AUTOSAR XML (schema 4-3-0)
package /VehicleProject
  system System
    system mapping System_MPPNG
      data-mappings:
        sender-receiver-to-signal-mapping={data-element=SwitchDetectionNeeded2L3.SwitchDetectionNeeded2L3, system-signal=SwitchDetectionNeeded2L3}
        sender-receiver-to-signal-mapping={data-element=FSP1SwitchStatusL3.FSP1SwitchStatusL3, system-signal=FSP1SwitchStatusL3}
        sender-receiver-to-signal-mapping={data-element=FSP2SwitchStatusL3.FSP2SwitchStatusL3, system-signal=FSP2SwitchStatusL3}
        sender-receiver-to-signal-mapping={data-element=FSP2DiagInfoL3.FSP2DiagInfoL3, system-signal=FSP2DiagInfoL3}
        sender-receiver-to-signal-mapping={data-element=FSP1ResponseErrorL3.FSP1ResponseErrorL3, system-signal=FSP1ResponseErrorL3}
        sender-receiver-to-signal-mapping={data-element=LIN_TCP_KnobPostionStatus.LIN_TCP_KnobPostionStatus, system-signal=LIN_TCP_KnobPostionStatus}
        sender-receiver-to-signal-mapping={data-element=SwitchDetectionNeeded1L3.SwitchDetectionNeeded1L3, system-signal=SwitchDetectionNeeded1L3}
        sender-receiver-to-signal-mapping={data-element=FSP1DiagInfoL3.FSP1DiagInfoL3, system-signal=FSP1DiagInfoL3}
        sender-receiver-to-signal-mapping={data-element=SwitchDetectionResp2L3.SwitchDetectionResp2L3, system-signal=SwitchDetectionResp2L3}
        sender-receiver-to-signal-mapping={data-element=SwitchDetectionResp1L3.SwitchDetectionResp1L3, system-signal=SwitchDetectionResp1L3}
        sender-receiver-to-signal-mapping={data-element=ResponseErrorTCP.ResponseErrorTCP, system-signal=ResponseErrorTCP}
        sender-receiver-to-signal-mapping={data-element=LIN_TCP_ABS_ButtonStatus.LIN_TCP_ABS_ButtonStatus, system-signal=LIN_TCP_ABS_ButtonStatus}
        sender-receiver-to-signal-mapping={data-element=LIN_TCP_TCS_ButtonStatus.LIN_TCP_TCS_ButtonStatus, system-signal=LIN_TCP_TCS_ButtonStatus}
        sender-receiver-to-signal-mapping={data-element=FSP2ResponseErrorL3.FSP2ResponseErrorL3, system-signal=FSP2ResponseErrorL3}
        sender-receiver-to-signal-mapping={data-element=DiagInfoTCP.DiagInfoTCP, system-signal=DiagInfoTCP}
        sender-receiver-to-signal-mapping={data-element=LIN_TCP_ATC_ButtonStatus.LIN_TCP_ATC_ButtonStatus, system-signal=LIN_TCP_ATC_ButtonStatus}
        sender-receiver-to-signal-mapping={data-element=LIN_TCP_ESC_ButtonStatus.LIN_TCP_ESC_ButtonStatus, system-signal=LIN_TCP_ESC_ButtonStatus}
        sender-receiver-to-signal-mapping={data-element=ATC_Indication.ATC_Indication, system-signal=ATC_Indication}
        sender-receiver-to-signal-mapping={data-element=ABS_Indication.ABS_Indication, system-signal=ABS_Indication}
        sender-receiver-to-signal-mapping={data-element=ESC_Indication.ESC_Indication, system-signal=ESC_Indication}
        sender-receiver-to-signal-mapping={data-element=FSP1IndicationCmdL3.FSP1IndicationCmdL3, system-signal=FSP1IndicationCmdL3}
        sender-receiver-to-signal-mapping={data-element=TCS_Indication.TCS_Indication, system-signal=TCS_Indication}
        sender-receiver-to-signal-mapping={data-element=FSP2IndicationCmdL3.FSP2IndicationCmdL3, system-signal=FSP2IndicationCmdL3}
        sender-receiver-to-signal-mapping={data-element=Debug_PVT_SCIM_Ctrl_BHS3.Debug_PVT_SCIM_Ctrl_BHS3, system-signal=Debug_PVT_SCIM_Ctrl_BHS3}
        sender-receiver-to-signal-mapping={data-element=Debug_PVT_SCIM_Ctrl_BHS2.Debug_PVT_SCIM_Ctrl_BHS2, system-signal=Debug_PVT_SCIM_Ctrl_BHS2}
        sender-receiver-to-signal-mapping={data-element=Debug_PVT_SCIM_Ctrl_BHS1.Debug_PVT_SCIM_Ctrl_BHS1, system-signal=Debug_PVT_SCIM_Ctrl_BHS1}
        sender-receiver-to-signal-mapping={data-element=Debug_PVT_SCIM_Ctrl_BHS4.Debug_PVT_SCIM_Ctrl_BHS4, system-signal=Debug_PVT_SCIM_Ctrl_BHS4}
        sender-receiver-to-signal-mapping={data-element=Debug_PVT_SCIM_RD_BHS3_Volt.Debug_PVT_SCIM_RD_BHS3_Volt, system-signal=Debug_PVT_SCIM_RD_BHS3_Volt}
        sender-receiver-to-signal-mapping={data-element=Debug_PVT_SCIM_RD_BHS1_Volt.Debug_PVT_SCIM_RD_BHS1_Volt, system-signal=Debug_PVT_SCIM_RD_BHS1_Volt}
        sender-receiver-to-signal-mapping={data-element=Debug_PVT_SCIM_RD_BHS3_Fault.Debug_PVT_SCIM_RD_BHS3_Fault, system-signal=Debug_PVT_SCIM_RD_BHS3_Fault}
        sender-receiver-to-signal-mapping={data-element=Debug_PVT_SCIM_RD_BHS1_Fault.Debug_PVT_SCIM_RD_BHS1_Fault, system-signal=Debug_PVT_SCIM_RD_BHS1_Fault}
        sender-receiver-to-signal-mapping={data-element=Debug_PVT_SCIM_RD_BHS2_Fault.Debug_PVT_SCIM_RD_BHS2_Fault, system-signal=Debug_PVT_SCIM_RD_BHS2_Fault}
        sender-receiver-to-signal-mapping={data-element=Debug_PVT_SCIM_RD_BHS2_Volt.Debug_PVT_SCIM_RD_BHS2_Volt, system-signal=Debug_PVT_SCIM_RD_BHS2_Volt}
        sender-receiver-to-signal-mapping={data-element=Debug_PVT_SCIM_RD_BHS4_Fault.Debug_PVT_SCIM_RD_BHS4_Fault, system-signal=Debug_PVT_SCIM_RD_BHS4_Fault}
        sender-receiver-to-signal-mapping={data-element=Debug_PVT_SCIM_RD_BHS4_Volt.Debug_PVT_SCIM_RD_BHS4_Volt, system-signal=Debug_PVT_SCIM_RD_BHS4_Volt}
        sender-receiver-to-signal-mapping={data-element=Debug_PVT_SCIM_Ctrl_DaiPullUp.Debug_PVT_SCIM_Ctrl_DaiPullUp, system-signal=Debug_PVT_SCIM_Ctrl_DAIPullUp}
        sender-receiver-to-signal-mapping={data-element=Debug_PVT_SCIM_RD_ADI09.Debug_PVT_SCIM_RD_ADI09, system-signal=Debug_PVT_SCIM_RD_ADI09}
        sender-receiver-to-signal-mapping={data-element=Debug_PVT_SCIM_RD_ADI16.Debug_PVT_SCIM_RD_ADI16, system-signal=Debug_PVT_SCIM_RD_ADI16}
        sender-receiver-to-signal-mapping={data-element=Debug_PVT_SCIM_RD_ADI07.Debug_PVT_SCIM_RD_ADI07, system-signal=Debug_PVT_SCIM_RD_ADI07}
        sender-receiver-to-signal-mapping={data-element=Debug_PVT_SCIM_RD_ADI02.Debug_PVT_SCIM_RD_ADI02, system-signal=Debug_PVT_SCIM_RD_ADI02}
        sender-receiver-to-signal-mapping={data-element=Debug_PVT_SCIM_RD_DAI1.Debug_PVT_SCIM_RD_DAI1, system-signal=Debug_PVT_SCIM_RD_DAI1}
        sender-receiver-to-signal-mapping={data-element=Debug_PVT_SCIM_RD_ADI10.Debug_PVT_SCIM_RD_ADI10, system-signal=Debug_PVT_SCIM_RD_ADI10}
        sender-receiver-to-signal-mapping={data-element=Debug_PVT_SCIM_RD_ADI06.Debug_PVT_SCIM_RD_ADI06, system-signal=Debug_PVT_SCIM_RD_ADI06}
        sender-receiver-to-signal-mapping={data-element=Debug_PVT_SCIM_RD_ADI01.Debug_PVT_SCIM_RD_ADI01, system-signal=Debug_PVT_SCIM_RD_ADI01}
        sender-receiver-to-signal-mapping={data-element=Debug_PVT_SCIM_RD_ADI03.Debug_PVT_SCIM_RD_ADI03, system-signal=Debug_PVT_SCIM_RD_ADI03}
        sender-receiver-to-signal-mapping={data-element=Debug_PVT_SCIM_RD_ADI11.Debug_PVT_SCIM_RD_ADI11, system-signal=Debug_PVT_SCIM_RD_ADI11}
        sender-receiver-to-signal-mapping={data-element=Debug_PVT_SCIM_RD_ADI14.Debug_PVT_SCIM_RD_ADI14, system-signal=Debug_PVT_SCIM_RD_ADI14}
        sender-receiver-to-signal-mapping={data-element=Debug_PVT_SCIM_RD_ADI13.Debug_PVT_SCIM_RD_ADI13, system-signal=Debug_PVT_SCIM_RD_ADI13}
        sender-receiver-to-signal-mapping={data-element=Debug_PVT_SCIM_RD_ADI04.Debug_PVT_SCIM_RD_ADI04, system-signal=Debug_PVT_SCIM_RD_ADI04}
        sender-receiver-to-signal-mapping={data-element=Debug_PVT_SCIM_RD_ADI12.Debug_PVT_SCIM_RD_ADI12, system-signal=Debug_PVT_SCIM_RD_ADI12}
        sender-receiver-to-signal-mapping={data-element=Debug_PVT_SCIM_RD_ADI15.Debug_PVT_SCIM_RD_ADI15, system-signal=Debug_PVT_SCIM_RD_ADI15}
        sender-receiver-to-signal-mapping={data-element=Debug_PVT_SCIM_RD_ADI05.Debug_PVT_SCIM_RD_ADI05, system-signal=Debug_PVT_SCIM_RD_ADI05}
        sender-receiver-to-signal-mapping={data-element=Debug_PVT_SCIM_RD_DAI2.Debug_PVT_SCIM_RD_DAI2, system-signal=Debug_PVT_SCIM_RD_DAI2}
        sender-receiver-to-signal-mapping={data-element=Debug_PVT_SCIM_RD_ADI08.Debug_PVT_SCIM_RD_ADI08, system-signal=Debug_PVT_SCIM_RD_ADI08}
        sender-receiver-to-signal-mapping={data-element=LIN_BunkH2RoofhatchCloseBtn_St.LIN_BunkH2RoofhatchCloseBtn_St, system-signal=LIN_BunkH2RoofhatchCloseBtn_St}
        sender-receiver-to-signal-mapping={data-element=LIN_BunkH2LockButtonStatus.LIN_BunkH2LockButtonStatus, system-signal=LIN_BunkH2LockButtonStatus}
        sender-receiver-to-signal-group-mapping={data-element=LIN_AlmClkSetCurAlm_rqst_sg.LIN_AlmClkSetCurAlm_rqst_sg, signal-group=LIN_AlmClkSetCurAlm_rqst_sg, type-mapping=sender-rec-record-type-mapping=record-element-mappings=[{implementation-record-element=LIN_AlmClkSetCurAlm_rqst_SetMin, system-signal=LIN_AlmClkSetCurAlm_rqst_SetMin}, {implementation-record-element=LIN_AlmClkSetCurAlm_rqst_Type, system-signal=LIN_AlmClkSetCurAlm_rqst_Type}, {implementation-record-element=LIN_AlmClkSetCurAlm_rqst_ID, system-signal=LIN_AlmClkSetCurAlm_rqst_ID}, {implementation-record-element=LIN_AlmClkSetCurAlm_rqst_SetHr, system-signal=LIN_AlmClkSetCurAlm_rqst_SetHr}, {implementation-record-element=LIN_AlmClkSetCurAlm_rqst_Stat, system-signal=LIN_AlmClkSetCurAlm_rqst_Stat}]}
        sender-receiver-to-signal-mapping={data-element=LIN_BunkH2IntLightIncBtn_stat.LIN_BunkH2IntLightIncBtn_stat, system-signal=LIN_BunkH2IntLightIncBtn_stat}
        sender-receiver-to-signal-mapping={data-element=LIN_BunkH2Fade_ButtonStatus.LIN_BunkH2Fade_ButtonStatus, system-signal=LIN_BunkH2Fade_ButtonStatus}
        sender-receiver-to-signal-mapping={data-element=SwitchDetectionNeeded1L1.SwitchDetectionNeeded1L1, system-signal=SwitchDetectionNeeded1L1}
        sender-receiver-to-signal-mapping={data-element=LIN_BunkH2PowerWinOpenPSBtn_st.LIN_BunkH2PowerWinOpenPSBtn_st, system-signal=LIN_BunkH2PowerWinOpenPSBtn_st}
        sender-receiver-to-signal-mapping={data-element=LIN_IntLghtDimmingLvlDecBtn_s.LIN_IntLghtDimmingLvlDecBtn_s, system-signal=LIN_IntLghtDimmingLvlDecBtn_s}
        sender-receiver-to-signal-mapping={data-element=LIN_IntLghtDimmingLvlIncBtn_s.LIN_IntLghtDimmingLvlIncBtn_s, system-signal=LIN_IntLghtDimmingLvlIncBtn_s}
        sender-receiver-to-signal-mapping={data-element=ResponseErrorLECM2.ResponseErrorLECM2, system-signal=ResponseErrorLECM2}
        sender-receiver-to-signal-group-mapping={data-element=LIN_BunkH2PHTi_rqs_sg.LIN_BunkH2PHTi_rqs_sg, signal-group=LIN_BunkH2PHTi_rqs_sg, type-mapping=sender-rec-record-type-mapping=record-element-mappings=[{implementation-record-element=LIN_BunkH2PHTi_rqs_StartTimeHr, system-signal=LIN_BunkH2PHTi_rqs_StartTimeHr}, {implementation-record-element=LIN_BunkH2PHTi_rqs_Timer_cmd, system-signal=LIN_BunkH2PHTi_rqs_Timer_cmd}, {implementation-record-element=LIN_BunkH2PHTi_rqs_DurnTimeHr, system-signal=LIN_BunkH2PHTi_rqs_DurnTimeHr}, {implementation-record-element=LIN_BunkH2PHTi_rqs_StartTimeMin, system-signal=LIN_BunkH2PHTi_rqs_StartTimeMin}, {implementation-record-element=LIN_BunkH2PHTi_rqs_DurnTimeMin, system-signal=LIN_BunkH2PHTi_rqs_DurnTimeMin}]}
        sender-receiver-to-signal-mapping={data-element=ResponseErrorLECMBasic.ResponseErrorLECMBasic, system-signal=ResponseErrorLECMBasic}
        sender-receiver-to-signal-mapping={data-element=LIN_BunkH2VolumeDown_ButtonSta.LIN_BunkH2VolumeDown_ButtonSta, system-signal=LIN_BunkH2VolumeDown_ButtonSta}
        sender-receiver-to-signal-mapping={data-element=LIN_BunkH2IntLightDecBtn_stat.LIN_BunkH2IntLightDecBtn_stat, system-signal=LIN_BunkH2IntLightDecBtn_stat}
        sender-receiver-to-signal-mapping={data-element=FSP2DiagInfoL1.FSP2DiagInfoL1, system-signal=FSP2DiagInfoL1}
        sender-receiver-to-signal-mapping={data-element=LIN_BunkBAudioOnOff_ButtonStat.LIN_BunkBAudioOnOff_ButtonStat, system-signal=LIN_BunkBAudioOnOff_ButtonStat}
        sender-receiver-to-signal-mapping={data-element=DiagInfoLECM2.DiagInfoLECM2, system-signal=DiagInfoLECM2}
        sender-receiver-to-signal-mapping={data-element=SwitchDetectionNeeded2L1.SwitchDetectionNeeded2L1, system-signal=SwitchDetectionNeeded2L1}
        sender-receiver-to-signal-mapping={data-element=DiagInfoLECMBasic.DiagInfoLECMBasic, system-signal=DiagInfoLECMBasic}
        sender-receiver-to-signal-mapping={data-element=LIN_BunkBVolumeDown_ButtonStat.LIN_BunkBVolumeDown_ButtonStat, system-signal=LIN_BunkBVolumeDown_ButtonStat}
        sender-receiver-to-signal-mapping={data-element=LIN_IntLghtModeSelrFreeWheel_s.LIN_IntLghtModeSelrFreeWheel_s, system-signal=LIN_IntLghtModeSelrFreeWheel_s}
        sender-receiver-to-signal-mapping={data-element=LIN_BunkH2OnOFF_ButtonStatus.LIN_BunkH2OnOFF_ButtonStatus, system-signal=LIN_BunkH2OnOFF_ButtonStatus}
        sender-receiver-to-signal-mapping={data-element=FSP1ResponseErrorL1.FSP1ResponseErrorL1, system-signal=FSP1ResponseErrorL1}
        sender-receiver-to-signal-mapping={data-element=LIN_BunkH2VolumeUp_ButtonStatu.LIN_BunkH2VolumeUp_ButtonStatu, system-signal=LIN_BunkH2VolumeUp_ButtonStatu}
        sender-receiver-to-signal-mapping={data-element=ResponseErrorILCP1.ResponseErrorILCP1, system-signal=ResponseErrorILCP1}
        sender-receiver-to-signal-mapping={data-element=LIN_BunkH2Phone_ButtonStatus.LIN_BunkH2Phone_ButtonStatus, system-signal=LIN_BunkH2Phone_ButtonStatus}
        sender-receiver-to-signal-mapping={data-element=FSP2ResponseErrorL1.FSP2ResponseErrorL1, system-signal=FSP2ResponseErrorL1}
        sender-receiver-to-signal-mapping={data-element=LIN_BunkH2PowerWinCloseDSBtn_s.LIN_BunkH2PowerWinCloseDSBtn_s, system-signal=LIN_BunkH2PowerWinCloseDSBtn_s}
        sender-receiver-to-signal-mapping={data-element=LIN_BunkH2PowerWinOpenDSBtn_st.LIN_BunkH2PowerWinOpenDSBtn_st, system-signal=LIN_BunkH2PowerWinOpenDSBtn_st}
        sender-receiver-to-signal-mapping={data-element=LIN_DoorAutoFuncBtn_stat.LIN_DoorAutoFuncBtn_stat, system-signal=LIN_DoorAutoFuncBtn_stat}
        sender-receiver-to-signal-mapping={data-element=LIN_BunkH2TempDec_ButtonStatus.LIN_BunkH2TempDec_ButtonStatus, system-signal=LIN_BunkH2TempDec_ButtonStatus}
        sender-receiver-to-signal-mapping={data-element=LIN_BunkBVolumeUp_ButtonStat.LIN_BunkBVolumeUp_ButtonStat, system-signal=LIN_BunkBVolumeUp_ButtonStat}
        sender-receiver-to-signal-mapping={data-element=LIN_BunkBIntLightActvnBtn_stat.LIN_BunkBIntLightActvnBtn_stat, system-signal=LIN_BunkBIntLightActvnBtn_stat}
        sender-receiver-to-signal-mapping={data-element=LIN_BunkH2PowerWinClosePSBtn_s.LIN_BunkH2PowerWinClosePSBtn_s, system-signal=LIN_BunkH2PowerWinClosePSBtn_s}
        sender-receiver-to-signal-mapping={data-element=LIN_BunkBParkHeater_ButtonStat.LIN_BunkBParkHeater_ButtonStat, system-signal=LIN_BunkBParkHeater_ButtonStat}
        sender-receiver-to-signal-mapping={data-element=LIN_BunkH2ParkHeater_ButtonSta.LIN_BunkH2ParkHeater_ButtonSta, system-signal=LIN_BunkH2ParkHeater_ButtonSta}
        sender-receiver-to-signal-mapping={data-element=LIN_BunkBTempInc_ButtonStat.LIN_BunkBTempInc_ButtonStat, system-signal=LIN_BunkBTempInc_ButtonStat}
        sender-receiver-to-signal-mapping={data-element=LIN_BunkH2AudioOnOff_ButtonSta.LIN_BunkH2AudioOnOff_ButtonSta, system-signal=LIN_BunkH2AudioOnOff_ButtonSta}
        sender-receiver-to-signal-mapping={data-element=SwitchDetectionResp2L1.SwitchDetectionResp2L1, system-signal=SwitchDetectionResp2L1}
        sender-receiver-to-signal-mapping={data-element=LIN_BunkH2IntLightActvnBtn_sta.LIN_BunkH2IntLightActvnBtn_sta, system-signal=LIN_BunkH2IntLightActvnBtn_sta}
        sender-receiver-to-signal-mapping={data-element=LIN_BunkH2RoofhatchOpenBtn_Sta.LIN_BunkH2RoofhatchOpenBtn_Sta, system-signal=LIN_BunkH2RoofhatchOpenBtn_Sta}
        sender-receiver-to-signal-mapping={data-element=SwitchDetectionResp1L1.SwitchDetectionResp1L1, system-signal=SwitchDetectionResp1L1}
        sender-receiver-to-signal-mapping={data-element=FSP1DiagInfoL1.FSP1DiagInfoL1, system-signal=FSP1DiagInfoL1}
        sender-receiver-to-signal-mapping={data-element=DiagInfoILCP1.DiagInfoILCP1, system-signal=DiagInfoILCP1}
        sender-receiver-to-signal-mapping={data-element=LIN_BunkBTempDec_ButtonStat.LIN_BunkBTempDec_ButtonStat, system-signal=LIN_BunkBTempDec_ButtonStat}
        sender-receiver-to-signal-mapping={data-element=LIN_BunkH2TempInc_ButtonStatus.LIN_BunkH2TempInc_ButtonStatus, system-signal=LIN_BunkH2TempInc_ButtonStatus}
        sender-receiver-to-signal-mapping={data-element=LIN_IntLightMaxModeInd_cmd.LIN_IntLightMaxModeInd_cmd, system-signal=LIN_IntLightMaxModeInd_cmd}
        sender-receiver-to-signal-group-mapping={data-element=LIN_AlmClkCurAlarm_stat_sg.LIN_AlmClkCurAlarm_stat_sg, signal-group=LIN_AlmClkCurAlarm_stat_sg, type-mapping=sender-rec-record-type-mapping=record-element-mappings=[{implementation-record-element=LIN_AlmClkCurAlarm_stat_Stat, system-signal=LIN_AlmClkCurAlarm_stat_Stat}, {implementation-record-element=LIN_AlmClkCurAlarm_stat_SetHr, system-signal=LIN_AlmClkCurAlarm_stat_SetHr}, {implementation-record-element=LIN_AlmClkCurAlarm_stat_Type, system-signal=LIN_AlmClkCurAlarm_stat_Type}, {implementation-record-element=LIN_AlmClkCurAlarm_stat_SetMin, system-signal=LIN_AlmClkCurAlarm_stat_SetMin}, {implementation-record-element=LIN_AlmClkCurAlarm_stat_ID, system-signal=LIN_AlmClkCurAlarm_stat_ID}]}
        sender-receiver-to-signal-mapping={data-element=LIN_DoorAutoFuncInd_cmd.LIN_DoorAutoFuncInd_cmd, system-signal=LIN_DoorAutoFuncInd_cmd}
        sender-receiver-to-signal-mapping={data-element=LIN_IntLightNightModeInd_cmd.LIN_IntLightNightModeInd_cmd, system-signal=LIN_IntLightNightModeInd_cmd}
        sender-receiver-to-signal-mapping={data-element=LIN_IntLightRestingModeInd_cmd.LIN_IntLightRestingModeInd_cmd, system-signal=LIN_IntLightRestingModeInd_cmd}
        sender-receiver-to-signal-mapping={data-element=LIN_AudioVolumeIndicationCmd.LIN_AudioVolumeIndicationCmd, system-signal=LIN_AudioVolumeIndicationCmd}
        sender-receiver-to-signal-mapping={data-element=LIN_IntLghtOffModeInd_cmd.LIN_IntLghtOffModeInd_cmd, system-signal=LIN_IntLghtOffModeInd_cmd}
        sender-receiver-to-signal-mapping={data-element=FSP2IndicationCmdL1.FSP2IndicationCmdL1, system-signal=FSP2IndicationCmdL1}
        sender-receiver-to-signal-mapping={data-element=LIN_PhoneButtonIndication_cmd.LIN_PhoneButtonIndication_cmd, system-signal=LIN_PhoneButtonIndication_cmd}
        sender-receiver-to-signal-mapping={data-element=LIN_AudioSystemStatus.LIN_AudioSystemStatus, system-signal=LIN_AudioSystemStatus}
        sender-receiver-to-signal-mapping={data-element=LIN_BTStatus.LIN_BTStatus, system-signal=LIN_BTStatus}
        sender-receiver-to-signal-mapping={data-element=DoorLock_stat.DoorLock_stat, system-signal=DoorLock_stat}
        sender-receiver-to-signal-mapping={data-element=LIN_IntLghtLvlIndScaled_cmd.LIN_IntLghtLvlIndScaled_cmd, system-signal=LIN_IntLghtLvlIndScaled_cmd}
        sender-receiver-to-signal-group-mapping={data-element=LIN_IntLghtModeInd_cmd_sg.LIN_IntLghtModeInd_cmd_sg, signal-group=LIN_IntLghtModeInd_cmd_sg, type-mapping=sender-rec-record-type-mapping=record-element-mappings=[{implementation-record-element=LIN_IntLghtModeInd_cmd_EventFlag, system-signal=LIN_IntLghtModeInd_cmd_EventFlag}, {implementation-record-element=LIN_IntLghtModeInd_cmd_IL_Mode, system-signal=LIN_IntLghtModeInd_cmd_IL_Mode}]}
        sender-receiver-to-signal-mapping={data-element=FSP3ResponseErrorL2.FSP3ResponseErrorL2, system-signal=FSP3ResponseErrorL2}
        sender-receiver-to-signal-mapping={data-element=FSP1SwitchStatusL2.FSP1SwitchStatusL2, system-signal=FSP1SwitchStatusL2}
        sender-receiver-to-signal-mapping={data-element=SwitchDetectionResp1L2.SwitchDetectionResp1L2, system-signal=SwitchDetectionResp1L2}
        sender-receiver-to-signal-mapping={data-element=SwitchDetectionNeeded2L2.SwitchDetectionNeeded2L2, system-signal=SwitchDetectionNeeded2L2}
        sender-receiver-to-signal-mapping={data-element=FSP3SwitchStatusL2.FSP3SwitchStatusL2, system-signal=FSP3SwitchStatusL2}
        sender-receiver-to-signal-mapping={data-element=FSP3DiagInfoL2.FSP3DiagInfoL2, system-signal=FSP3DiagInfoL2}
        sender-receiver-to-signal-mapping={data-element=FSP1DiagInfoL2.FSP1DiagInfoL2, system-signal=FSP1DiagInfoL2}
        sender-receiver-to-signal-mapping={data-element=FSP4ResponseErrorL2.FSP4ResponseErrorL2, system-signal=FSP4ResponseErrorL2}
        sender-receiver-to-signal-mapping={data-element=FSP4DiagInfoL2.FSP4DiagInfoL2, system-signal=FSP4DiagInfoL2}
        sender-receiver-to-signal-mapping={data-element=FSP2DiagInfoL2.FSP2DiagInfoL2, system-signal=FSP2DiagInfoL2}
        sender-receiver-to-signal-mapping={data-element=SwitchDetectionResp4L2.SwitchDetectionResp4L2, system-signal=SwitchDetectionResp4L2}
        sender-receiver-to-signal-mapping={data-element=FSP4SwitchStatusL2.FSP4SwitchStatusL2, system-signal=FSP4SwitchStatusL2}
        sender-receiver-to-signal-mapping={data-element=FSP1ResponseErrorL2.FSP1ResponseErrorL2, system-signal=FSP1ResponseErrorL2}
        sender-receiver-to-signal-mapping={data-element=SwitchDetectionResp2L2.SwitchDetectionResp2L2, system-signal=SwitchDetectionResp2L2}
        sender-receiver-to-signal-mapping={data-element=FSP2SwitchStatusL2.FSP2SwitchStatusL2, system-signal=FSP2SwitchStatusL2}
        sender-receiver-to-signal-mapping={data-element=SwitchDetectionNeeded1L2.SwitchDetectionNeeded1L2, system-signal=SwitchDetectionNeeded1L2}
        sender-receiver-to-signal-mapping={data-element=FSP2ResponseErrorL2.FSP2ResponseErrorL2, system-signal=FSP2ResponseErrorL2}
        sender-receiver-to-signal-mapping={data-element=SwitchDetectionNeeded3L2.SwitchDetectionNeeded3L2, system-signal=SwitchDetectionNeeded3L2}
        sender-receiver-to-signal-mapping={data-element=SwitchDetectionResp3L2.SwitchDetectionResp3L2, system-signal=SwitchDetectionResp3L2}
        sender-receiver-to-signal-mapping={data-element=SwitchDetectionNeeded4L2.SwitchDetectionNeeded4L2, system-signal=SwitchDetectionNeeded4L2}
        sender-receiver-to-signal-mapping={data-element=FSP3IndicationCmdL2.FSP3IndicationCmdL2, system-signal=FSP3IndicationCmdL2}
        sender-receiver-to-signal-mapping={data-element=FSP1IndicationCmdL2.FSP1IndicationCmdL2, system-signal=FSP1IndicationCmdL2}
        sender-receiver-to-signal-mapping={data-element=FSP4IndicationCmdL2.FSP4IndicationCmdL2, system-signal=FSP4IndicationCmdL2}
        sender-receiver-to-signal-mapping={data-element=FSP2IndicationCmdL2.FSP2IndicationCmdL2, system-signal=FSP2IndicationCmdL2}
        sender-receiver-to-signal-mapping={data-element=ResponseErrorELCP1.ResponseErrorELCP1, system-signal=ResponseErrorELCP1}
        sender-receiver-to-signal-mapping={data-element=SwitchDetectionNeeded1L5.SwitchDetectionNeeded1L5, system-signal=SwitchDetectionNeeded1L5}
        sender-receiver-to-signal-mapping={data-element=LIN_WRDownButtonStatus.LIN_WRDownButtonStatus, system-signal=LIN_WRDownButtonStatus}
        sender-receiver-to-signal-mapping={data-element=FSP1SwitchStatusL4.FSP1SwitchStatusL4, system-signal=FSP1SwitchStatusL4}
        sender-receiver-to-signal-mapping={data-element=LIN_IntLghtNightModeBt2_s.LIN_IntLghtNightModeBt2_s, system-signal=LIN_IntLghtNightModeBt2_s}
        sender-receiver-to-signal-mapping={data-element=ResponseErrorILCP2.ResponseErrorILCP2, system-signal=ResponseErrorILCP2}
        sender-receiver-to-signal-mapping={data-element=FSP1ResponseErrorL4.FSP1ResponseErrorL4, system-signal=FSP1ResponseErrorL4}
        sender-receiver-to-signal-mapping={data-element=LIN_DifflockMode_Wheelstatus.LIN_DifflockMode_Wheelstatus, system-signal=LIN_DifflockMode_Wheelstatus}
        sender-receiver-to-signal-mapping={data-element=LIN_LKSPushButton.LIN_LKSPushButton, system-signal=LIN_LKSPushButton}
        sender-receiver-to-signal-mapping={data-element=LIN_LightMode_Status_2.LIN_LightMode_Status_2, system-signal=LIN_LightMode_Status_2}
        sender-receiver-to-signal-mapping={data-element=LIN_SpeedControlModeWheelStat.LIN_SpeedControlModeWheelStat, system-signal=LIN_SpeedControlModeWheelStat}
        sender-receiver-to-signal-mapping={data-element=LIN_BackButtonStatus.LIN_BackButtonStatus, system-signal=LIN_BackButtonStatus}
        sender-receiver-to-signal-mapping={data-element=LIN_MemButtonStatus.LIN_MemButtonStatus, system-signal=LIN_MemButtonStatus}
        sender-receiver-to-signal-mapping={data-element=SwitchDetectionResp1L4.SwitchDetectionResp1L4, system-signal=SwitchDetectionResp1L4}
        sender-receiver-to-signal-mapping={data-element=LIN_SelectButtonStatus.LIN_SelectButtonStatus, system-signal=LIN_SelectButtonStatus}
        sender-receiver-to-signal-mapping={data-element=LIN_IntLghtDimmingLvlFreeWhl_s.LIN_IntLghtDimmingLvlFreeWhl_s, system-signal=LIN_IntLghtDimmingLvlFreeWhl_s}
        sender-receiver-to-signal-mapping={data-element=LIN_FogLightRear_ButtonStat_1.LIN_FogLightRear_ButtonStat_1, system-signal=LIN_FogLightRear_ButtonStat_1}
        sender-receiver-to-signal-mapping={data-element=LIN_SpeedControlModeButtonStat.LIN_SpeedControlModeButtonStat, system-signal=LIN_SpeedControlModeButtonStat}
        sender-receiver-to-signal-mapping={data-element=DiagInfoDLFW.DiagInfoDLFW, system-signal=DiagInfoDLFW}
        sender-receiver-to-signal-mapping={data-element=LIN_FogLightRear_ButtonStat_2.LIN_FogLightRear_ButtonStat_2, system-signal=LIN_FogLightRear_ButtonStat_2}
        sender-receiver-to-signal-mapping={data-element=LIN_StopButtonStatus.LIN_StopButtonStatus, system-signal=LIN_StopButtonStatus}
        sender-receiver-to-signal-mapping={data-element=DiagInfoRCECS.DiagInfoRCECS, system-signal=DiagInfoRCECS}
        sender-receiver-to-signal-mapping={data-element=LIN_LightMode_Status_1.LIN_LightMode_Status_1, system-signal=LIN_LightMode_Status_1}
        sender-receiver-to-signal-mapping={data-element=LIN_WRUpButtonStatus.LIN_WRUpButtonStatus, system-signal=LIN_WRUpButtonStatus}
        sender-receiver-to-signal-mapping={data-element=LIN_DifflockDeactivationBtn_st.LIN_DifflockDeactivationBtn_st, system-signal=LIN_DifflockDeactivationBtn_st}
        sender-receiver-to-signal-mapping={data-element=LIN_IntLghtCenterBtnFreeWhl_s.LIN_IntLghtCenterBtnFreeWhl_s, system-signal=LIN_IntLghtCenterBtnFreeWhl_s}
        sender-receiver-to-signal-mapping={data-element=SwitchDetectionResp1L5.SwitchDetectionResp1L5, system-signal=SwitchDetectionResp1L5}
        sender-receiver-to-signal-mapping={data-element=FSP1DiagInfoL5.FSP1DiagInfoL5, system-signal=FSP1DiagInfoL5}
        sender-receiver-to-signal-mapping={data-element=LIN_EscButtonMuddySiteStatus.LIN_EscButtonMuddySiteStatus, system-signal=LIN_EscButtonMuddySiteStatus}
        sender-receiver-to-signal-mapping={data-element=FSP1SwitchStatusL5.FSP1SwitchStatusL5, system-signal=FSP1SwitchStatusL5}
        sender-receiver-to-signal-mapping={data-element=SwitchDetectionNeeded1L4.SwitchDetectionNeeded1L4, system-signal=SwitchDetectionNeeded1L4}
        sender-receiver-to-signal-mapping={data-element=LIN_AdjustButtonStatus.LIN_AdjustButtonStatus, system-signal=LIN_AdjustButtonStatus}
        sender-receiver-to-signal-mapping={data-element=ResponseErrorDLFW.ResponseErrorDLFW, system-signal=ResponseErrorDLFW}
        sender-receiver-to-signal-mapping={data-element=LIN_BlackPanelMode_ButtonStat.LIN_BlackPanelMode_ButtonStat, system-signal=LIN_BlackPanelMode_ButtonStat}
        sender-receiver-to-signal-mapping={data-element=FSP1DiagInfoL4.FSP1DiagInfoL4, system-signal=FSP1DiagInfoL4}
        sender-receiver-to-signal-mapping={data-element=LIN_FCWPushButton.LIN_FCWPushButton, system-signal=LIN_FCWPushButton}
        sender-receiver-to-signal-mapping={data-element=ResponseErrorRCECS.ResponseErrorRCECS, system-signal=ResponseErrorRCECS}
        sender-receiver-to-signal-mapping={data-element=DiagInfoELCP2.DiagInfoELCP2, system-signal=DiagInfoELCP2}
        sender-receiver-to-signal-mapping={data-element=DiagInfoCCFW.DiagInfoCCFW, system-signal=DiagInfoCCFW}
        sender-receiver-to-signal-mapping={data-element=DiagInfoILCP2.DiagInfoILCP2, system-signal=DiagInfoILCP2}
        sender-receiver-to-signal-mapping={data-element=DiagInfoELCP1.DiagInfoELCP1, system-signal=DiagInfoELCP1}
        sender-receiver-to-signal-mapping={data-element=LIN_BackLightDimming_Status.LIN_BackLightDimming_Status, system-signal=LIN_BackLightDimming_Status}
        sender-receiver-to-signal-mapping={data-element=FSP1ResponseErrorL5.FSP1ResponseErrorL5, system-signal=FSP1ResponseErrorL5}
        sender-receiver-to-signal-mapping={data-element=LIN_DRL_ButtonStatus.LIN_DRL_ButtonStatus, system-signal=LIN_DRL_ButtonStatus}
        sender-receiver-to-signal-mapping={data-element=ResponseErrorELCP2.ResponseErrorELCP2, system-signal=ResponseErrorELCP2}
        sender-receiver-to-signal-mapping={data-element=ResponseErrorCCFW.ResponseErrorCCFW, system-signal=ResponseErrorCCFW}
        sender-receiver-to-signal-mapping={data-element=LIN_LevelingThumbwheel_stat.LIN_LevelingThumbwheel_stat, system-signal=LIN_LevelingThumbwheel_stat}
        sender-receiver-to-signal-mapping={data-element=LIN_Offroad_ButtonStatus.LIN_Offroad_ButtonStatus, system-signal=LIN_Offroad_ButtonStatus}
        sender-receiver-to-signal-mapping={data-element=LIN_FogLightFront_ButtonStat_2.LIN_FogLightFront_ButtonStat_2, system-signal=LIN_FogLightFront_ButtonStat_2}
        sender-receiver-to-signal-mapping={data-element=LIN_RearWorkProjector_BtnStat.LIN_RearWorkProjector_BtnStat, system-signal=LIN_RearWorkProjector_BtnStat}
        sender-receiver-to-signal-mapping={data-element=LIN_HeadLampUpDown_SwitchStatu.LIN_HeadLampUpDown_SwitchStatu, system-signal=LIN_HeadLampUpDown_SwitchStatu}
        sender-receiver-to-signal-mapping={data-element=LIN_FogLightFront_ButtonStat_1.LIN_FogLightFront_ButtonStat_1, system-signal=LIN_FogLightFront_ButtonStat_1}
        sender-receiver-to-signal-mapping={data-element=LIN_IntLghtMaxModeBtnPnl2_s.LIN_IntLghtMaxModeBtnPnl2_s, system-signal=LIN_IntLghtMaxModeBtnPnl2_s}
        sender-receiver-to-signal-mapping={data-element=LIN_IntLghtRestModeBtnPnl2_s.LIN_IntLghtRestModeBtnPnl2_s, system-signal=LIN_IntLghtRestModeBtnPnl2_s}
        sender-receiver-to-signal-mapping={data-element=LIN_ACCOrCCIndication.LIN_ACCOrCCIndication, system-signal=LIN_ACCOrCCIndication}
        sender-receiver-to-signal-mapping={data-element=LIN_M3_DeviceIndication.LIN_M3_DeviceIndication, system-signal=LIN_M3_DeviceIndication}
        sender-receiver-to-signal-mapping={data-element=LIN_EscButtonMuddySiteDeviceIn.LIN_EscButtonMuddySiteDeviceIn, system-signal=LIN_EscButtonMuddySiteDeviceIn}
        sender-receiver-to-signal-mapping={data-element=LIN_M1_DeviceIndication.LIN_M1_DeviceIndication, system-signal=LIN_M1_DeviceIndication}
        sender-receiver-to-signal-mapping={data-element=LIN_ShortPulseMaxLength.LIN_ShortPulseMaxLength, system-signal=LIN_ShortPulseMaxLength}
        sender-receiver-to-signal-mapping={data-element=LIN_FCW_DeviceIndication.LIN_FCW_DeviceIndication, system-signal=LIN_FCW_DeviceIndication}
        sender-receiver-to-signal-mapping={data-element=LIN_DrivingLightPlus_Indicatio.LIN_DrivingLightPlus_Indicatio, system-signal=LIN_DrivingLightPlus_Indicatio}
        sender-receiver-to-signal-mapping={data-element=LIN_RearFog_Indication.LIN_RearFog_Indication, system-signal=LIN_RearFog_Indication}
        sender-receiver-to-signal-mapping={data-element=LIN_Offroad_Indication.LIN_Offroad_Indication, system-signal=LIN_Offroad_Indication}
        sender-receiver-to-signal-mapping={data-element=LIN_LKS_DeviceIndication.LIN_LKS_DeviceIndication, system-signal=LIN_LKS_DeviceIndication}
        sender-receiver-to-signal-mapping={data-element=LIN_Down_DeviceIndication.LIN_Down_DeviceIndication, system-signal=LIN_Down_DeviceIndication}
        sender-receiver-to-signal-mapping={data-element=LIN_M2_DeviceIndication.LIN_M2_DeviceIndication, system-signal=LIN_M2_DeviceIndication}
        sender-receiver-to-signal-mapping={data-element=LIN_ParkingLight_Indication.LIN_ParkingLight_Indication, system-signal=LIN_ParkingLight_Indication}
        sender-receiver-to-signal-mapping={data-element=FSP1IndicationCmdL5.FSP1IndicationCmdL5, system-signal=FSP1IndicationCmdL5}
        sender-receiver-to-signal-mapping={data-element=LIN_FrontFog_Indication.LIN_FrontFog_Indication, system-signal=LIN_FrontFog_Indication}
        sender-receiver-to-signal-mapping={data-element=LIN_ASLIndication.LIN_ASLIndication, system-signal=LIN_ASLIndication}
        sender-receiver-to-signal-mapping={data-element=LIN_DaytimeRunningLight_Indica.LIN_DaytimeRunningLight_Indica, system-signal=LIN_DaytimeRunningLight_Indica}
        sender-receiver-to-signal-mapping={data-element=LIN_DifflockOnOff_Indication.LIN_DifflockOnOff_Indication, system-signal=LIN_DifflockOnOff_Indication}
        sender-receiver-to-signal-mapping={data-element=LIN_RearWorkProjector_Indicati.LIN_RearWorkProjector_Indicati, system-signal=LIN_RearWorkProjector_Indicati}
        sender-receiver-to-signal-mapping={data-element=FSP1IndicationCmdL4.FSP1IndicationCmdL4, system-signal=FSP1IndicationCmdL4}
        sender-receiver-to-signal-mapping={data-element=LIN_Adjust_DeviceIndication.LIN_Adjust_DeviceIndication, system-signal=LIN_Adjust_DeviceIndication}
        sender-receiver-to-signal-mapping={data-element=LIN_DrivingLight_Indication.LIN_DrivingLight_Indication, system-signal=LIN_DrivingLight_Indication}
        sender-receiver-to-signal-mapping={data-element=LIN_Up_DeviceIndication.LIN_Up_DeviceIndication, system-signal=LIN_Up_DeviceIndication}
        sender-receiver-to-signal-mapping={data-element=Debug_PVT_SCIM_Ctrl_LivingPullUp.Debug_PVT_SCIM_Ctrl_LivingPullUp, system-signal=Debug_PVT_SCIM_Ctrl_LivingPullUp}
        sender-receiver-to-signal-mapping={data-element=Debug_PVT_SCIM_Ctrl_ParkedPullUp.Debug_PVT_SCIM_Ctrl_ParkedPullUp, system-signal=Debug_PVT_SCIM_Ctrl_ParkedPullUp}
        sender-receiver-to-signal-mapping={data-element=ABSInhibitRqstDenied.ABSInhibitRqstDenied, system-signal=ABSInhibitRqstDenied}
        sender-receiver-to-signal-mapping={data-element=Debug_PVT_SCIM_RD_12VLivingVolt.Debug_PVT_SCIM_RD_12VLivingVolt, system-signal=Debug_PVT_SCIM_RD_12VLivingVolt}
        sender-receiver-to-signal-mapping={data-element=Debug_PVT_SCIM_RD_12VParkedVolt.Debug_PVT_SCIM_RD_12VParkedVolt, system-signal=Debug_PVT_SCIM_RD_12VParkedVolt}
        sender-receiver-to-signal-mapping={data-element=Debug_PVT_SCIM_RD_12VDCDCFault.Debug_PVT_SCIM_RD_12VDCDCFault, system-signal=Debug_PVT_SCIM_RD_12VDCDCFault}
        sender-receiver-to-signal-mapping={data-element=Debug_PVT_SCIM_RD_12VDCDCVolt.Debug_PVT_SCIM_RD_12VDCDCVolt, system-signal=Debug_PVT_SCIM_RD_12VDCDCVolt}
        sender-receiver-to-signal-mapping={data-element=Debug_PVT_SCIM_RD_VBAT.Debug_PVT_SCIM_RD_VBAT, system-signal=Debug_PVT_SCIM_RD_VBAT}
        sender-receiver-to-signal-mapping={data-element=Debug_PVT_SCIM_Ctrl_WLS2Freq.Debug_PVT_SCIM_Ctrl_WLS2Freq, system-signal=Debug_PVT_SCIM_Ctrl_WLS2Freq}
        sender-receiver-to-signal-mapping={data-element=Debug_PVT_SCIM_Ctrl_WLS3.Debug_PVT_SCIM_Ctrl_WLS3, system-signal=Debug_PVT_SCIM_Ctrl_WLS3}
        sender-receiver-to-signal-mapping={data-element=Debug_PVT_SCIM_Ctrl_WLS2Duty.Debug_PVT_SCIM_Ctrl_WLS2Duty, system-signal=Debug_PVT_SCIM_Ctrl_WLS2Duty}
        sender-receiver-to-signal-mapping={data-element=Debug_PVT_SCIM_Ctrl_WLS1_Duty.Debug_PVT_SCIM_Ctrl_WLS1_Duty, system-signal=Debug_PVT_SCIM_Ctrl_WLS1_Duty}
        sender-receiver-to-signal-mapping={data-element=Debug_PVT_SCIM_Ctrl_WHS1.Debug_PVT_SCIM_Ctrl_WHS1, system-signal=Debug_PVT_SCIM_Ctrl_WHS1}
        sender-receiver-to-signal-mapping={data-element=Debug_PVT_SCIM_Ctrl_WHS1_Freq.Debug_PVT_SCIM_Ctrl_WHS1_Freq, system-signal=Debug_PVT_SCIM_Ctrl_WHS1_Freq}
        sender-receiver-to-signal-mapping={data-element=Debug_PVT_SCIM_Ctrl_WLS3Duty.Debug_PVT_SCIM_Ctrl_WLS3Duty, system-signal=Debug_PVT_SCIM_Ctrl_WLS3Duty}
        sender-receiver-to-signal-mapping={data-element=Debug_PVT_SCIM_Ctrl_WHS1_Duty.Debug_PVT_SCIM_Ctrl_WHS1_Duty, system-signal=Debug_PVT_SCIM_Ctrl_WHS1_Duty}
        sender-receiver-to-signal-mapping={data-element=Debug_PVT_SCIM_Ctrl_WLS1_Freq.Debug_PVT_SCIM_Ctrl_WLS1_Freq, system-signal=Debug_PVT_SCIM_Ctrl_WLS1_Freq}
        sender-receiver-to-signal-mapping={data-element=Debug_PVT_SCIM_Ctrl_WLS3Freq.Debug_PVT_SCIM_Ctrl_WLS3Freq, system-signal=Debug_PVT_SCIM_Ctrl_WLS3Freq}
        sender-receiver-to-signal-mapping={data-element=Debug_PVT_SCIM_Ctrl_WHS2.Debug_PVT_SCIM_Ctrl_WHS2, system-signal=Debug_PVT_SCIM_Ctrl_WHS2}
        sender-receiver-to-signal-mapping={data-element=Debug_PVT_SCIM_Ctrl_WLS2.Debug_PVT_SCIM_Ctrl_WLS2, system-signal=Debug_PVT_SCIM_Ctrl_WLS2}
        sender-receiver-to-signal-mapping={data-element=Debug_PVT_SCIM_Ctrl_WHS2_Freq.Debug_PVT_SCIM_Ctrl_WHS2_Freq, system-signal=Debug_PVT_SCIM_Ctrl_WHS2_Freq}
        sender-receiver-to-signal-mapping={data-element=Debug_PVT_SCIM_Ctrl_WLS1.Debug_PVT_SCIM_Ctrl_WLS1, system-signal=Debug_PVT_SCIM_Ctrl_WLS1}
        sender-receiver-to-signal-mapping={data-element=Debug_PVT_SCIM_Ctrl_WHS2_Duty.Debug_PVT_SCIM_Ctrl_WHS2_Duty, system-signal=Debug_PVT_SCIM_Ctrl_WHS2_Duty}
        sender-receiver-to-signal-mapping={data-element=Debug_PVT_SCIM_RD_WLS1_Duty.Debug_PVT_SCIM_RD_WLS1_Duty, system-signal=Debug_PVT_SCIM_RD_WLS1_Duty}
        sender-receiver-to-signal-mapping={data-element=Debug_PVT_SCIM_RD_WLS3_Freq.Debug_PVT_SCIM_RD_WLS3_Freq, system-signal=Debug_PVT_SCIM_RD_WLS3_Freq}
        sender-receiver-to-signal-mapping={data-element=Debug_PVT_SCIM_RD_WHS1_Volt.Debug_PVT_SCIM_RD_WHS1_Volt, system-signal=Debug_PVT_SCIM_RD_WHS1_Volt}
        sender-receiver-to-signal-mapping={data-element=Debug_PVT_SCIM_RD_WLS2_Fault.Debug_PVT_SCIM_RD_WLS2_Fault, system-signal=Debug_PVT_SCIM_RD_WLS2_Fault}
        sender-receiver-to-signal-mapping={data-element=Debug_PVT_SCIM_RD_WLS1_Volt.Debug_PVT_SCIM_RD_WLS1_Volt, system-signal=Debug_PVT_SCIM_RD_WLS1_Volt}
        sender-receiver-to-signal-mapping={data-element=Debug_PVT_SCIM_RD_WHS2_Volt.Debug_PVT_SCIM_RD_WHS2_Volt, system-signal=Debug_PVT_SCIM_RD_WHS2_Volt}
        sender-receiver-to-signal-mapping={data-element=Debug_PVT_SCIM_RD_WHS1_Duty.Debug_PVT_SCIM_RD_WHS1_Duty, system-signal=Debug_PVT_SCIM_RD_WHS1_Duty}
        sender-receiver-to-signal-mapping={data-element=Debug_PVT_SCIM_RD_WLS2_Volt.Debug_PVT_SCIM_RD_WLS2_Volt, system-signal=Debug_PVT_SCIM_RD_WLS2_Volt}
        sender-receiver-to-signal-mapping={data-element=Debug_PVT_SCIM_RD_WLS1_Fault.Debug_PVT_SCIM_RD_WLS1_Fault, system-signal=Debug_PVT_SCIM_RD_WLS1_Fault}
        sender-receiver-to-signal-mapping={data-element=Debug_PVT_SCIM_RD_WLS2_Freq.Debug_PVT_SCIM_RD_WLS2_Freq, system-signal=Debug_PVT_SCIM_RD_WLS2_Freq}
        sender-receiver-to-signal-mapping={data-element=Debug_PVT_SCIM_RD_WHS2_Duty.Debug_PVT_SCIM_RD_WHS2_Duty, system-signal=Debug_PVT_SCIM_RD_WHS2_Duty}
        sender-receiver-to-signal-mapping={data-element=Debug_PVT_SCIM_RD_WHS1_Freq.Debug_PVT_SCIM_RD_WHS1_Freq, system-signal=Debug_PVT_SCIM_RD_WHS1_Freq}
        sender-receiver-to-signal-mapping={data-element=Debug_PVT_SCIM_RD_WLS2_Duty.Debug_PVT_SCIM_RD_WLS2_Duty, system-signal=Debug_PVT_SCIM_RD_WLS2_Duty}
        sender-receiver-to-signal-mapping={data-element=Debug_PVT_SCIM_RD_WHS1_Fault.Debug_PVT_SCIM_RD_WHS1_Fault, system-signal=Debug_PVT_SCIM_RD_WHS1_Fault}
        sender-receiver-to-signal-mapping={data-element=Debug_PVT_SCIM_RD_WHS2_Freq.Debug_PVT_SCIM_RD_WHS2_Freq, system-signal=Debug_PVT_SCIM_RD_WHS2_Freq}
        sender-receiver-to-signal-mapping={data-element=Debug_PVT_SCIM_RD_WLS3_Duty.Debug_PVT_SCIM_RD_WLS3_Duty, system-signal=Debug_PVT_SCIM_RD_WLS3_Duty}
        sender-receiver-to-signal-mapping={data-element=Debug_PVT_SCIM_RD_WHS2_Fault.Debug_PVT_SCIM_RD_WHS2_Fault, system-signal=Debug_PVT_SCIM_RD_WHS2_Fault}
        sender-receiver-to-signal-mapping={data-element=Debug_PVT_SCIM_RD_WLS3_Fault.Debug_PVT_SCIM_RD_WLS3_Fault, system-signal=Debug_PVT_SCIM_RD_WLS3_Fault}
        sender-receiver-to-signal-mapping={data-element=Debug_PVT_SCIM_RD_WLS1_Freq.Debug_PVT_SCIM_RD_WLS1_Freq, system-signal=Debug_PVT_SCIM_RD_WLS1_Freq}
        sender-receiver-to-signal-mapping={data-element=Debug_PVT_SCIM_RD_WLS3_Volt.Debug_PVT_SCIM_RD_WLS3_Volt, system-signal=Debug_PVT_SCIM_RD_WLS3_Volt}
        sender-receiver-to-signal-mapping={data-element=Debug_PVT_SCIM_Ctrl_12VDCDC.Debug_PVT_SCIM_Ctrl_12VDCDC, system-signal=Debug_PVT_SCIM_Ctrl_12VDCDC}
        sender-receiver-to-signal-mapping={data-element=Debug_PVT_SCIM_Ctrl_12VParked.Debug_PVT_SCIM_Ctrl_12VParked, system-signal=Debug_PVT_SCIM_Ctrl_12VParked}
        sender-receiver-to-signal-mapping={data-element=Debug_PVT_SCIM_Ctrl_12VLiving.Debug_PVT_SCIM_Ctrl_12VLiving, system-signal=Debug_PVT_SCIM_Ctrl_12VLiving}
    root-software-compositions:
      root sw composition prototype EcuSwComposition: software-composition=ECU_Composition
package /ECUCompositionTypes
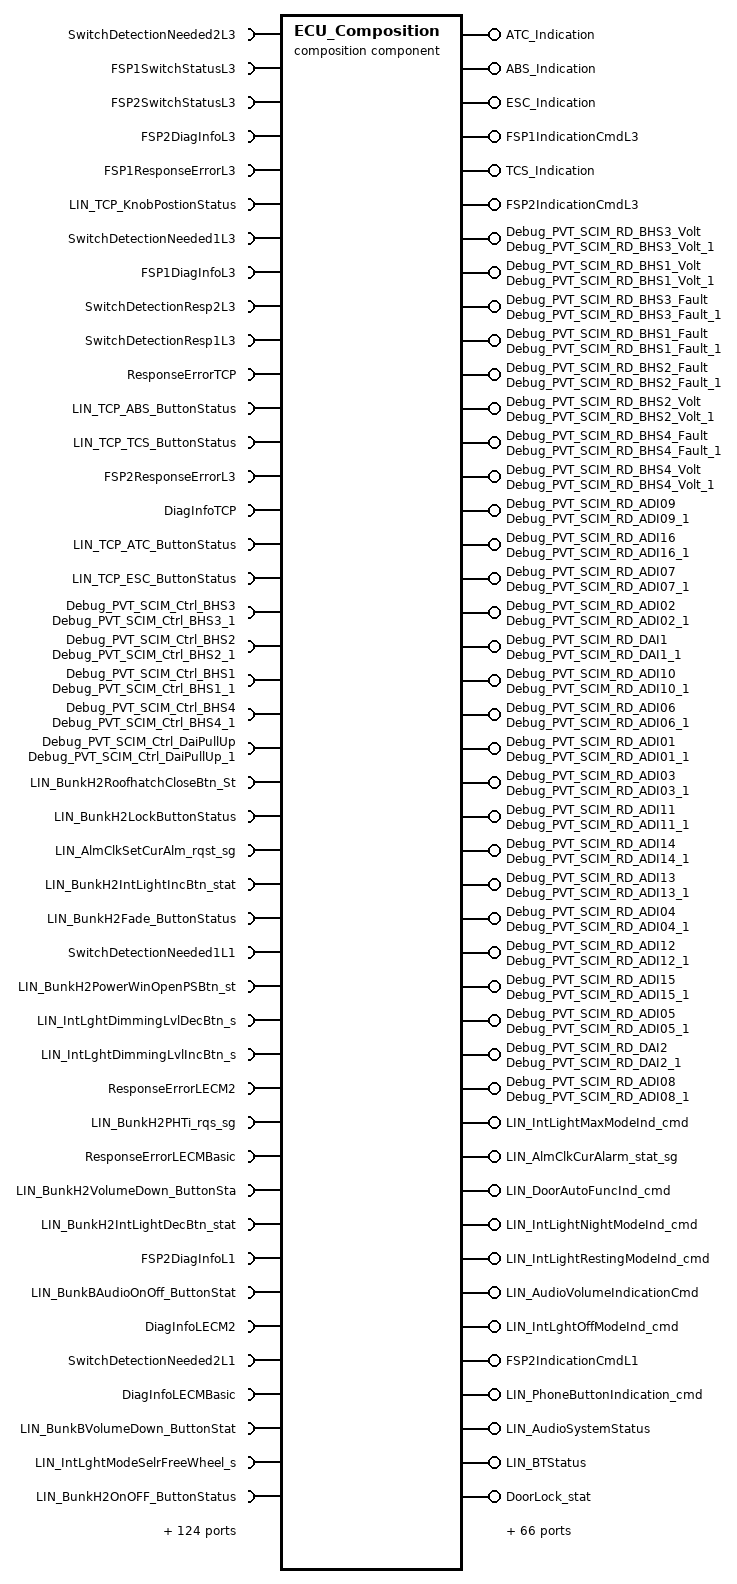
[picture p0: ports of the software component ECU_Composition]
  composition sw component type ECU_Composition
    17 x require port:
      SwitchDetectionNeeded2L3: nonqueued-receiver-com-spec{data-element=SwitchDetectionNeeded2L3, init-value=0}, required-interface=SwitchDetectionNeeded2L3
      FSP1SwitchStatusL3: nonqueued-receiver-com-spec{data-element=FSP1SwitchStatusL3, init-value=0}, required-interface=FSP1SwitchStatusL3
      FSP2SwitchStatusL3: nonqueued-receiver-com-spec{data-element=FSP2SwitchStatusL3, init-value=0}, required-interface=FSP2SwitchStatusL3
      FSP2DiagInfoL3: nonqueued-receiver-com-spec{data-element=FSP2DiagInfoL3, init-value=0}, required-interface=FSP2DiagInfoL3
      FSP1ResponseErrorL3: nonqueued-receiver-com-spec{data-element=FSP1ResponseErrorL3, init-value=0}, required-interface=FSP1ResponseErrorL3
      LIN_TCP_KnobPostionStatus: nonqueued-receiver-com-spec{data-element=LIN_TCP_KnobPostionStatus, init-value=7}, required-interface=LIN_TCP_KnobPostionStatus
      SwitchDetectionNeeded1L3: nonqueued-receiver-com-spec{data-element=SwitchDetectionNeeded1L3, init-value=0}, required-interface=SwitchDetectionNeeded1L3
      FSP1DiagInfoL3: nonqueued-receiver-com-spec{data-element=FSP1DiagInfoL3, init-value=0}, required-interface=FSP1DiagInfoL3
      SwitchDetectionResp2L3: nonqueued-receiver-com-spec{data-element=SwitchDetectionResp2L3, init-value=8 x 0}, required-interface=SwitchDetectionResp2L3
      SwitchDetectionResp1L3: nonqueued-receiver-com-spec{data-element=SwitchDetectionResp1L3, init-value=8 x 0}, required-interface=SwitchDetectionResp1L3
      ResponseErrorTCP: nonqueued-receiver-com-spec{data-element=ResponseErrorTCP, init-value=0}, required-interface=ResponseErrorTCP
      LIN_TCP_ABS_ButtonStatus: nonqueued-receiver-com-spec{data-element=LIN_TCP_ABS_ButtonStatus, init-value=3}, required-interface=LIN_TCP_ABS_ButtonStatus
      LIN_TCP_TCS_ButtonStatus: nonqueued-receiver-com-spec{data-element=LIN_TCP_TCS_ButtonStatus, init-value=3}, required-interface=LIN_TCP_TCS_ButtonStatus
      FSP2ResponseErrorL3: nonqueued-receiver-com-spec{data-element=FSP2ResponseErrorL3, init-value=0}, required-interface=FSP2ResponseErrorL3
      DiagInfoTCP: nonqueued-receiver-com-spec{data-element=DiagInfoTCP, init-value=0}, required-interface=DiagInfoTCP
      LIN_TCP_ATC_ButtonStatus: nonqueued-receiver-com-spec{data-element=LIN_TCP_ATC_ButtonStatus, init-value=3}, required-interface=LIN_TCP_ATC_ButtonStatus
      LIN_TCP_ESC_ButtonStatus: nonqueued-receiver-com-spec{data-element=LIN_TCP_ESC_ButtonStatus, init-value=3}, required-interface=LIN_TCP_ESC_ButtonStatus
    6 x provide port:
      ATC_Indication: nonqueued-sender-com-spec{data-element=ATC_Indication, init-value=3}, provided-interface=ATC_Indication
      ABS_Indication: nonqueued-sender-com-spec{data-element=ABS_Indication, init-value=3}, provided-interface=ABS_Indication
      ESC_Indication: nonqueued-sender-com-spec{data-element=ESC_Indication, init-value=3}, provided-interface=ESC_Indication
      FSP1IndicationCmdL3: nonqueued-sender-com-spec{data-element=FSP1IndicationCmdL3, init-value=0}, provided-interface=FSP1IndicationCmdL3
      TCS_Indication: nonqueued-sender-com-spec{data-element=TCS_Indication, init-value=3}, provided-interface=TCS_Indication
      FSP2IndicationCmdL3: nonqueued-sender-com-spec{data-element=FSP2IndicationCmdL3, init-value=0}, provided-interface=FSP2IndicationCmdL3
    4 x require port:
      Debug_PVT_SCIM_Ctrl_BHS3: nonqueued-receiver-com-spec{data-element=Debug_PVT_SCIM_Ctrl_BHS3, init-value=0}, required-interface=Debug_PVT_SCIM_Ctrl_BHS3_1
      Debug_PVT_SCIM_Ctrl_BHS2: nonqueued-receiver-com-spec{data-element=Debug_PVT_SCIM_Ctrl_BHS2, init-value=0}, required-interface=Debug_PVT_SCIM_Ctrl_BHS2_1
      Debug_PVT_SCIM_Ctrl_BHS1: nonqueued-receiver-com-spec{data-element=Debug_PVT_SCIM_Ctrl_BHS1, init-value=0}, required-interface=Debug_PVT_SCIM_Ctrl_BHS1_1
      Debug_PVT_SCIM_Ctrl_BHS4: nonqueued-receiver-com-spec{data-element=Debug_PVT_SCIM_Ctrl_BHS4, init-value=0}, required-interface=Debug_PVT_SCIM_Ctrl_BHS4_1
    8 x provide port:
      Debug_PVT_SCIM_RD_BHS3_Volt: nonqueued-sender-com-spec{data-element=Debug_PVT_SCIM_RD_BHS3_Volt, init-value=0}, provided-interface=Debug_PVT_SCIM_RD_BHS3_Volt_1
      Debug_PVT_SCIM_RD_BHS1_Volt: nonqueued-sender-com-spec{data-element=Debug_PVT_SCIM_RD_BHS1_Volt, init-value=0}, provided-interface=Debug_PVT_SCIM_RD_BHS1_Volt_1
      Debug_PVT_SCIM_RD_BHS3_Fault: nonqueued-sender-com-spec{data-element=Debug_PVT_SCIM_RD_BHS3_Fault, init-value=0}, provided-interface=Debug_PVT_SCIM_RD_BHS3_Fault_1
      Debug_PVT_SCIM_RD_BHS1_Fault: nonqueued-sender-com-spec{data-element=Debug_PVT_SCIM_RD_BHS1_Fault, init-value=0}, provided-interface=Debug_PVT_SCIM_RD_BHS1_Fault_1
      Debug_PVT_SCIM_RD_BHS2_Fault: nonqueued-sender-com-spec{data-element=Debug_PVT_SCIM_RD_BHS2_Fault, init-value=0}, provided-interface=Debug_PVT_SCIM_RD_BHS2_Fault_1
      Debug_PVT_SCIM_RD_BHS2_Volt: nonqueued-sender-com-spec{data-element=Debug_PVT_SCIM_RD_BHS2_Volt, init-value=0}, provided-interface=Debug_PVT_SCIM_RD_BHS2_Volt_1
      Debug_PVT_SCIM_RD_BHS4_Fault: nonqueued-sender-com-spec{data-element=Debug_PVT_SCIM_RD_BHS4_Fault, init-value=0}, provided-interface=Debug_PVT_SCIM_RD_BHS4_Fault_1
      Debug_PVT_SCIM_RD_BHS4_Volt: nonqueued-sender-com-spec{data-element=Debug_PVT_SCIM_RD_BHS4_Volt, init-value=0}, provided-interface=Debug_PVT_SCIM_RD_BHS4_Volt_1
    require port Debug_PVT_SCIM_Ctrl_DaiPullUp: nonqueued-receiver-com-spec{data-element=Debug_PVT_SCIM_Ctrl_DaiPullUp, init-value=0}, required-interface=Debug_PVT_SCIM_Ctrl_DaiPullUp_1
    18 x provide port:
      Debug_PVT_SCIM_RD_ADI09: nonqueued-sender-com-spec{data-element=Debug_PVT_SCIM_RD_ADI09, init-value=0}, provided-interface=Debug_PVT_SCIM_RD_ADI09_1
      Debug_PVT_SCIM_RD_ADI16: nonqueued-sender-com-spec{data-element=Debug_PVT_SCIM_RD_ADI16, init-value=0}, provided-interface=Debug_PVT_SCIM_RD_ADI16_1
      Debug_PVT_SCIM_RD_ADI07: nonqueued-sender-com-spec{data-element=Debug_PVT_SCIM_RD_ADI07, init-value=0}, provided-interface=Debug_PVT_SCIM_RD_ADI07_1
      Debug_PVT_SCIM_RD_ADI02: nonqueued-sender-com-spec{data-element=Debug_PVT_SCIM_RD_ADI02, init-value=0}, provided-interface=Debug_PVT_SCIM_RD_ADI02_1
      Debug_PVT_SCIM_RD_DAI1: nonqueued-sender-com-spec{data-element=Debug_PVT_SCIM_RD_DAI1, init-value=0}, provided-interface=Debug_PVT_SCIM_RD_DAI1_1
      Debug_PVT_SCIM_RD_ADI10: nonqueued-sender-com-spec{data-element=Debug_PVT_SCIM_RD_ADI10, init-value=0}, provided-interface=Debug_PVT_SCIM_RD_ADI10_1
      Debug_PVT_SCIM_RD_ADI06: nonqueued-sender-com-spec{data-element=Debug_PVT_SCIM_RD_ADI06, init-value=0}, provided-interface=Debug_PVT_SCIM_RD_ADI06_1
      Debug_PVT_SCIM_RD_ADI01: nonqueued-sender-com-spec{data-element=Debug_PVT_SCIM_RD_ADI01, init-value=0}, provided-interface=Debug_PVT_SCIM_RD_ADI01_1
      Debug_PVT_SCIM_RD_ADI03: nonqueued-sender-com-spec{data-element=Debug_PVT_SCIM_RD_ADI03, init-value=0}, provided-interface=Debug_PVT_SCIM_RD_ADI03_1
      Debug_PVT_SCIM_RD_ADI11: nonqueued-sender-com-spec{data-element=Debug_PVT_SCIM_RD_ADI11, init-value=0}, provided-interface=Debug_PVT_SCIM_RD_ADI11_1
      Debug_PVT_SCIM_RD_ADI14: nonqueued-sender-com-spec{data-element=Debug_PVT_SCIM_RD_ADI14, init-value=0}, provided-interface=Debug_PVT_SCIM_RD_ADI14_1
      Debug_PVT_SCIM_RD_ADI13: nonqueued-sender-com-spec{data-element=Debug_PVT_SCIM_RD_ADI13, init-value=0}, provided-interface=Debug_PVT_SCIM_RD_ADI13_1
      Debug_PVT_SCIM_RD_ADI04: nonqueued-sender-com-spec{data-element=Debug_PVT_SCIM_RD_ADI04, init-value=0}, provided-interface=Debug_PVT_SCIM_RD_ADI04_1
      Debug_PVT_SCIM_RD_ADI12: nonqueued-sender-com-spec{data-element=Debug_PVT_SCIM_RD_ADI12, init-value=0}, provided-interface=Debug_PVT_SCIM_RD_ADI12_1
      Debug_PVT_SCIM_RD_ADI15: nonqueued-sender-com-spec{data-element=Debug_PVT_SCIM_RD_ADI15, init-value=0}, provided-interface=Debug_PVT_SCIM_RD_ADI15_1
      Debug_PVT_SCIM_RD_ADI05: nonqueued-sender-com-spec{data-element=Debug_PVT_SCIM_RD_ADI05, init-value=0}, provided-interface=Debug_PVT_SCIM_RD_ADI05_1
      Debug_PVT_SCIM_RD_DAI2: nonqueued-sender-com-spec{data-element=Debug_PVT_SCIM_RD_DAI2, init-value=0}, provided-interface=Debug_PVT_SCIM_RD_DAI2_1
      Debug_PVT_SCIM_RD_ADI08: nonqueued-sender-com-spec{data-element=Debug_PVT_SCIM_RD_ADI08, init-value=0}, provided-interface=Debug_PVT_SCIM_RD_ADI08_1
    46 x require port:
      LIN_BunkH2RoofhatchCloseBtn_St: nonqueued-receiver-com-spec{data-element=LIN_BunkH2RoofhatchCloseBtn_St, init-value=3}, required-interface=LIN_BunkH2RoofhatchCloseBtn_St
      LIN_BunkH2LockButtonStatus: nonqueued-receiver-com-spec{data-element=LIN_BunkH2LockButtonStatus, init-value=3}, required-interface=LIN_BunkH2LockButtonStatus
      LIN_AlmClkSetCurAlm_rqst_sg: nonqueued-receiver-com-spec{data-element=LIN_AlmClkSetCurAlm_rqst_sg, init-value=fields=[LIN_AlmClkSetCurAlm_rqst_SetMin:63, LIN_AlmClkSetCurAlm_rqst_Type:7, LIN_AlmClkSetCurAlm_rqst_ID:127, LIN_AlmClkSetCurAlm_rqst_SetHr:31, LIN_AlmClkSetCurAlm_rqst_Stat:0]}, required-interface=LIN_AlmClkSetCurAlm_rqst_sg
      LIN_BunkH2IntLightIncBtn_stat: nonqueued-receiver-com-spec{data-element=LIN_BunkH2IntLightIncBtn_stat, init-value=3}, required-interface=LIN_BunkH2IntLightIncBtn_stat
      LIN_BunkH2Fade_ButtonStatus: nonqueued-receiver-com-spec{data-element=LIN_BunkH2Fade_ButtonStatus, init-value=3}, required-interface=LIN_BunkH2Fade_ButtonStatus
      SwitchDetectionNeeded1L1: nonqueued-receiver-com-spec{data-element=SwitchDetectionNeeded1L1, init-value=0}, required-interface=SwitchDetectionNeeded1L1
      LIN_BunkH2PowerWinOpenPSBtn_st: nonqueued-receiver-com-spec{data-element=LIN_BunkH2PowerWinOpenPSBtn_st, init-value=3}, required-interface=LIN_BunkH2PowerWinOpenPSBtn_st
      LIN_IntLghtDimmingLvlDecBtn_s: nonqueued-receiver-com-spec{data-element=LIN_IntLghtDimmingLvlDecBtn_s, init-value=3}, required-interface=LIN_IntLghtDimmingLvlDecBtn_s
      LIN_IntLghtDimmingLvlIncBtn_s: nonqueued-receiver-com-spec{data-element=LIN_IntLghtDimmingLvlIncBtn_s, init-value=3}, required-interface=LIN_IntLghtDimmingLvlIncBtn_s
      ResponseErrorLECM2: nonqueued-receiver-com-spec{data-element=ResponseErrorLECM2, init-value=0}, required-interface=ResponseErrorLECM2
      LIN_BunkH2PHTi_rqs_sg: nonqueued-receiver-com-spec{data-element=LIN_BunkH2PHTi_rqs_sg, init-value=fields=[LIN_BunkH2PHTi_rqs_StartTimeHr:255, LIN_BunkH2PHTi_rqs_Timer_cmd:7, LIN_BunkH2PHTi_rqs_DurnTimeHr:255, LIN_BunkH2PHTi_rqs_StartTimeMin:255, LIN_BunkH2PHTi_rqs_DurnTimeMin:255]}, required-interface=LIN_BunkH2PHTi_rqs_sg
      ResponseErrorLECMBasic: nonqueued-receiver-com-spec{data-element=ResponseErrorLECMBasic, init-value=0}, required-interface=ResponseErrorLECMBasic
      LIN_BunkH2VolumeDown_ButtonSta: nonqueued-receiver-com-spec{data-element=LIN_BunkH2VolumeDown_ButtonSta, init-value=3}, required-interface=LIN_BunkH2VolumeDown_ButtonSta
      LIN_BunkH2IntLightDecBtn_stat: nonqueued-receiver-com-spec{data-element=LIN_BunkH2IntLightDecBtn_stat, init-value=3}, required-interface=LIN_BunkH2IntLightDecBtn_stat
      FSP2DiagInfoL1: nonqueued-receiver-com-spec{data-element=FSP2DiagInfoL1, init-value=0}, required-interface=FSP2DiagInfoL1
      LIN_BunkBAudioOnOff_ButtonStat: nonqueued-receiver-com-spec{data-element=LIN_BunkBAudioOnOff_ButtonStat, init-value=3}, required-interface=LIN_BunkBAudioOnOff_ButtonStat
      DiagInfoLECM2: nonqueued-receiver-com-spec{data-element=DiagInfoLECM2, init-value=0}, required-interface=DiagInfoLECM2
      SwitchDetectionNeeded2L1: nonqueued-receiver-com-spec{data-element=SwitchDetectionNeeded2L1, init-value=0}, required-interface=SwitchDetectionNeeded2L1
      DiagInfoLECMBasic: nonqueued-receiver-com-spec{data-element=DiagInfoLECMBasic, init-value=0}, required-interface=DiagInfoLECMBasic
      LIN_BunkBVolumeDown_ButtonStat: nonqueued-receiver-com-spec{data-element=LIN_BunkBVolumeDown_ButtonStat, init-value=3}, required-interface=LIN_BunkBVolumeDown_ButtonStat
      LIN_IntLghtModeSelrFreeWheel_s: nonqueued-receiver-com-spec{data-element=LIN_IntLghtModeSelrFreeWheel_s, init-value=15}, required-interface=LIN_IntLghtModeSelrFreeWheel_s
      LIN_BunkH2OnOFF_ButtonStatus: nonqueued-receiver-com-spec{data-element=LIN_BunkH2OnOFF_ButtonStatus, init-value=3}, required-interface=LIN_BunkH2OnOFF_ButtonStatus
      FSP1ResponseErrorL1: nonqueued-receiver-com-spec{data-element=FSP1ResponseErrorL1, init-value=0}, required-interface=FSP1ResponseErrorL1
      LIN_BunkH2VolumeUp_ButtonStatu: nonqueued-receiver-com-spec{data-element=LIN_BunkH2VolumeUp_ButtonStatu, init-value=3}, required-interface=LIN_BunkH2VolumeUp_ButtonStatu
      ResponseErrorILCP1: nonqueued-receiver-com-spec{data-element=ResponseErrorILCP1, init-value=0}, required-interface=ResponseErrorILCP1
      LIN_BunkH2Phone_ButtonStatus: nonqueued-receiver-com-spec{data-element=LIN_BunkH2Phone_ButtonStatus, init-value=3}, required-interface=LIN_BunkH2Phone_ButtonStatus
      FSP2ResponseErrorL1: nonqueued-receiver-com-spec{data-element=FSP2ResponseErrorL1, init-value=0}, required-interface=FSP2ResponseErrorL1
      LIN_BunkH2PowerWinCloseDSBtn_s: nonqueued-receiver-com-spec{data-element=LIN_BunkH2PowerWinCloseDSBtn_s, init-value=3}, required-interface=LIN_BunkH2PowerWinCloseDSBtn_s
      LIN_BunkH2PowerWinOpenDSBtn_st: nonqueued-receiver-com-spec{data-element=LIN_BunkH2PowerWinOpenDSBtn_st, init-value=3}, required-interface=LIN_BunkH2PowerWinOpenDSBtn_st
      LIN_DoorAutoFuncBtn_stat: nonqueued-receiver-com-spec{data-element=LIN_DoorAutoFuncBtn_stat, init-value=3}, required-interface=LIN_DoorAutoFuncBtn_stat
      LIN_BunkH2TempDec_ButtonStatus: nonqueued-receiver-com-spec{data-element=LIN_BunkH2TempDec_ButtonStatus, init-value=3}, required-interface=LIN_BunkH2TempDec_ButtonStatus
      LIN_BunkBVolumeUp_ButtonStat: nonqueued-receiver-com-spec{data-element=LIN_BunkBVolumeUp_ButtonStat, init-value=3}, required-interface=LIN_BunkBVolumeUp_ButtonStat
      LIN_BunkBIntLightActvnBtn_stat: nonqueued-receiver-com-spec{data-element=LIN_BunkBIntLightActvnBtn_stat, init-value=3}, required-interface=LIN_BunkBIntLightActvnBtn_stat
      LIN_BunkH2PowerWinClosePSBtn_s: nonqueued-receiver-com-spec{data-element=LIN_BunkH2PowerWinClosePSBtn_s, init-value=3}, required-interface=LIN_BunkH2PowerWinClosePSBtn_s
      LIN_BunkBParkHeater_ButtonStat: nonqueued-receiver-com-spec{data-element=LIN_BunkBParkHeater_ButtonStat, init-value=3}, required-interface=LIN_BunkBParkHeater_ButtonStat
      LIN_BunkH2ParkHeater_ButtonSta: nonqueued-receiver-com-spec{data-element=LIN_BunkH2ParkHeater_ButtonSta, init-value=3}, required-interface=LIN_BunkH2ParkHeater_ButtonSta
      LIN_BunkBTempInc_ButtonStat: nonqueued-receiver-com-spec{data-element=LIN_BunkBTempInc_ButtonStat, init-value=3}, required-interface=LIN_BunkBTempInc_ButtonStat
      LIN_BunkH2AudioOnOff_ButtonSta: nonqueued-receiver-com-spec{data-element=LIN_BunkH2AudioOnOff_ButtonSta, init-value=3}, required-interface=LIN_BunkH2AudioOnOff_ButtonSta
      SwitchDetectionResp2L1: nonqueued-receiver-com-spec{data-element=SwitchDetectionResp2L1, init-value=8 x 0}, required-interface=SwitchDetectionResp2L1
      LIN_BunkH2IntLightActvnBtn_sta: nonqueued-receiver-com-spec{data-element=LIN_BunkH2IntLightActvnBtn_sta, init-value=3}, required-interface=LIN_BunkH2IntLightActvnBtn_sta
      LIN_BunkH2RoofhatchOpenBtn_Sta: nonqueued-receiver-com-spec{data-element=LIN_BunkH2RoofhatchOpenBtn_Sta, init-value=3}, required-interface=LIN_BunkH2RoofhatchOpenBtn_Sta
      SwitchDetectionResp1L1: nonqueued-receiver-com-spec{data-element=SwitchDetectionResp1L1, init-value=8 x 0}, required-interface=SwitchDetectionResp1L1
      FSP1DiagInfoL1: nonqueued-receiver-com-spec{data-element=FSP1DiagInfoL1, init-value=0}, required-interface=FSP1DiagInfoL1
      DiagInfoILCP1: nonqueued-receiver-com-spec{data-element=DiagInfoILCP1, init-value=0}, required-interface=DiagInfoILCP1
      LIN_BunkBTempDec_ButtonStat: nonqueued-receiver-com-spec{data-element=LIN_BunkBTempDec_ButtonStat, init-value=3}, required-interface=LIN_BunkBTempDec_ButtonStat
      LIN_BunkH2TempInc_ButtonStatus: nonqueued-receiver-com-spec{data-element=LIN_BunkH2TempInc_ButtonStatus, init-value=3}, required-interface=LIN_BunkH2TempInc_ButtonStatus
    14 x provide port:
      LIN_IntLightMaxModeInd_cmd: nonqueued-sender-com-spec{data-element=LIN_IntLightMaxModeInd_cmd, init-value=0}, provided-interface=LIN_IntLightMaxModeInd_cmd
      LIN_AlmClkCurAlarm_stat_sg: nonqueued-sender-com-spec{data-element=LIN_AlmClkCurAlarm_stat_sg, init-value=fields=[LIN_AlmClkCurAlarm_stat_Stat:0, LIN_AlmClkCurAlarm_stat_SetHr:31, LIN_AlmClkCurAlarm_stat_Type:7, LIN_AlmClkCurAlarm_stat_SetMin:63, LIN_AlmClkCurAlarm_stat_ID:127]}, provided-interface=LIN_AlmClkCurAlarm_stat_sg
      LIN_DoorAutoFuncInd_cmd: nonqueued-sender-com-spec{data-element=LIN_DoorAutoFuncInd_cmd, init-value=0}, provided-interface=LIN_DoorAutoFuncInd_cmd
      LIN_IntLightNightModeInd_cmd: nonqueued-sender-com-spec{data-element=LIN_IntLightNightModeInd_cmd, init-value=0}, provided-interface=LIN_IntLightNightModeInd_cmd
      LIN_IntLightRestingModeInd_cmd: nonqueued-sender-com-spec{data-element=LIN_IntLightRestingModeInd_cmd, init-value=0}, provided-interface=LIN_IntLightRestingModeInd_cmd
      LIN_AudioVolumeIndicationCmd: nonqueued-sender-com-spec{data-element=LIN_AudioVolumeIndicationCmd, init-value=0}, provided-interface=LIN_AudioVolumeIndicationCmd
      LIN_IntLghtOffModeInd_cmd: nonqueued-sender-com-spec{data-element=LIN_IntLghtOffModeInd_cmd, init-value=0}, provided-interface=LIN_IntLghtOffModeInd_cmd
      FSP2IndicationCmdL1: nonqueued-sender-com-spec{data-element=FSP2IndicationCmdL1, init-value=0}, provided-interface=FSP2IndicationCmdL1
      LIN_PhoneButtonIndication_cmd: nonqueued-sender-com-spec{data-element=LIN_PhoneButtonIndication_cmd, init-value=0}, provided-interface=LIN_PhoneButtonIndication_cmd
      LIN_AudioSystemStatus: nonqueued-sender-com-spec{data-element=LIN_AudioSystemStatus, init-value=3}, provided-interface=LIN_AudioSystemStatus
      LIN_BTStatus: nonqueued-sender-com-spec{data-element=LIN_BTStatus, init-value=3}, provided-interface=LIN_BTStatus
      DoorLock_stat: nonqueued-sender-com-spec{data-element=DoorLock_stat, init-value=15}, provided-interface=DoorLock_stat
      LIN_IntLghtLvlIndScaled_cmd: nonqueued-sender-com-spec{data-element=LIN_IntLghtLvlIndScaled_cmd, init-value=0}, provided-interface=LIN_IntLghtLvlIndScaled_cmd
      LIN_IntLghtModeInd_cmd_sg: nonqueued-sender-com-spec{data-element=LIN_IntLghtModeInd_cmd_sg, init-value=fields=[LIN_IntLghtModeInd_cmd_EventFlag:0, LIN_IntLghtModeInd_cmd_IL_Mode:7]}, provided-interface=LIN_IntLghtModeInd_cmd_sg
    20 x require port:
      FSP3ResponseErrorL2: nonqueued-receiver-com-spec{data-element=FSP3ResponseErrorL2, init-value=0}, required-interface=FSP3ResponseErrorL2
      FSP1SwitchStatusL2: nonqueued-receiver-com-spec{data-element=FSP1SwitchStatusL2, init-value=0}, required-interface=FSP1SwitchStatusL2
      SwitchDetectionResp1L2: nonqueued-receiver-com-spec{data-element=SwitchDetectionResp1L2, init-value=8 x 0}, required-interface=SwitchDetectionResp1L2
      SwitchDetectionNeeded2L2: nonqueued-receiver-com-spec{data-element=SwitchDetectionNeeded2L2, init-value=0}, required-interface=SwitchDetectionNeeded2L2
      FSP3SwitchStatusL2: nonqueued-receiver-com-spec{data-element=FSP3SwitchStatusL2, init-value=0}, required-interface=FSP3SwitchStatusL2
      FSP3DiagInfoL2: nonqueued-receiver-com-spec{data-element=FSP3DiagInfoL2, init-value=0}, required-interface=FSP3DiagInfoL2
      FSP1DiagInfoL2: nonqueued-receiver-com-spec{data-element=FSP1DiagInfoL2, init-value=0}, required-interface=FSP1DiagInfoL2
      FSP4ResponseErrorL2: nonqueued-receiver-com-spec{data-element=FSP4ResponseErrorL2, init-value=0}, required-interface=FSP4ResponseErrorL2
      FSP4DiagInfoL2: nonqueued-receiver-com-spec{data-element=FSP4DiagInfoL2, init-value=0}, required-interface=FSP4DiagInfoL2
      FSP2DiagInfoL2: nonqueued-receiver-com-spec{data-element=FSP2DiagInfoL2, init-value=0}, required-interface=FSP2DiagInfoL2
      SwitchDetectionResp4L2: nonqueued-receiver-com-spec{data-element=SwitchDetectionResp4L2, init-value=8 x 0}, required-interface=SwitchDetectionResp4L2
      FSP4SwitchStatusL2: nonqueued-receiver-com-spec{data-element=FSP4SwitchStatusL2, init-value=0}, required-interface=FSP4SwitchStatusL2
      FSP1ResponseErrorL2: nonqueued-receiver-com-spec{data-element=FSP1ResponseErrorL2, init-value=0}, required-interface=FSP1ResponseErrorL2
      SwitchDetectionResp2L2: nonqueued-receiver-com-spec{data-element=SwitchDetectionResp2L2, init-value=8 x 0}, required-interface=SwitchDetectionResp2L2
      FSP2SwitchStatusL2: nonqueued-receiver-com-spec{data-element=FSP2SwitchStatusL2, init-value=0}, required-interface=FSP2SwitchStatusL2
      SwitchDetectionNeeded1L2: nonqueued-receiver-com-spec{data-element=SwitchDetectionNeeded1L2, init-value=0}, required-interface=SwitchDetectionNeeded1L2
      FSP2ResponseErrorL2: nonqueued-receiver-com-spec{data-element=FSP2ResponseErrorL2, init-value=0}, required-interface=FSP2ResponseErrorL2
      SwitchDetectionNeeded3L2: nonqueued-receiver-com-spec{data-element=SwitchDetectionNeeded3L2, init-value=0}, required-interface=SwitchDetectionNeeded3L2
      SwitchDetectionResp3L2: nonqueued-receiver-com-spec{data-element=SwitchDetectionResp3L2, init-value=8 x 0}, required-interface=SwitchDetectionResp3L2
      SwitchDetectionNeeded4L2: nonqueued-receiver-com-spec{data-element=SwitchDetectionNeeded4L2, init-value=0}, required-interface=SwitchDetectionNeeded4L2
    4 x provide port:
      FSP3IndicationCmdL2: nonqueued-sender-com-spec{data-element=FSP3IndicationCmdL2, init-value=0}, provided-interface=FSP3IndicationCmdL2
      FSP1IndicationCmdL2: nonqueued-sender-com-spec{data-element=FSP1IndicationCmdL2, init-value=0}, provided-interface=FSP1IndicationCmdL2
      FSP4IndicationCmdL2: nonqueued-sender-com-spec{data-element=FSP4IndicationCmdL2, init-value=0}, provided-interface=FSP4IndicationCmdL2
      FSP2IndicationCmdL2: nonqueued-sender-com-spec{data-element=FSP2IndicationCmdL2, init-value=0}, provided-interface=FSP2IndicationCmdL2
    54 x require port:
      ResponseErrorELCP1: nonqueued-receiver-com-spec{data-element=ResponseErrorELCP1, init-value=0}, required-interface=ResponseErrorELCP1
      SwitchDetectionNeeded1L5: nonqueued-receiver-com-spec{data-element=SwitchDetectionNeeded1L5, init-value=0}, required-interface=SwitchDetectionNeeded1L5
      LIN_WRDownButtonStatus: nonqueued-receiver-com-spec{data-element=LIN_WRDownButtonStatus, init-value=7}, required-interface=LIN_WRDownButtonStatus
      FSP1SwitchStatusL4: nonqueued-receiver-com-spec{data-element=FSP1SwitchStatusL4, init-value=0}, required-interface=FSP1SwitchStatusL4
      LIN_IntLghtNightModeBt2_s: nonqueued-receiver-com-spec{data-element=LIN_IntLghtNightModeBt2_s, init-value=3}, required-interface=LIN_IntLghtNightModeBt2_s
      ResponseErrorILCP2: nonqueued-receiver-com-spec{data-element=ResponseErrorILCP2, init-value=0}, required-interface=ResponseErrorILCP2
      FSP1ResponseErrorL4: nonqueued-receiver-com-spec{data-element=FSP1ResponseErrorL4, init-value=0}, required-interface=FSP1ResponseErrorL4
      LIN_DifflockMode_Wheelstatus: nonqueued-receiver-com-spec{data-element=LIN_DifflockMode_Wheelstatus, init-value=15}, required-interface=LIN_DifflockMode_Wheelstatus
      LIN_LKSPushButton: nonqueued-receiver-com-spec{data-element=LIN_LKSPushButton, init-value=3}, required-interface=LIN_LKSPushButton
      LIN_LightMode_Status_2: nonqueued-receiver-com-spec{data-element=LIN_LightMode_Status_2, init-value=15}, required-interface=LIN_LightMode_Status_2
      LIN_SpeedControlModeWheelStat: nonqueued-receiver-com-spec{data-element=LIN_SpeedControlModeWheelStat, init-value=15}, required-interface=LIN_SpeedControlModeWheelStat
      LIN_BackButtonStatus: nonqueued-receiver-com-spec{data-element=LIN_BackButtonStatus, init-value=3}, required-interface=LIN_BackButtonStatus
      LIN_MemButtonStatus: nonqueued-receiver-com-spec{data-element=LIN_MemButtonStatus, init-value=3}, required-interface=LIN_MemButtonStatus
      SwitchDetectionResp1L4: nonqueued-receiver-com-spec{data-element=SwitchDetectionResp1L4, init-value=8 x 0}, required-interface=SwitchDetectionResp1L4
      LIN_SelectButtonStatus: nonqueued-receiver-com-spec{data-element=LIN_SelectButtonStatus, init-value=3}, required-interface=LIN_SelectButtonStatus
      LIN_IntLghtDimmingLvlFreeWhl_s: nonqueued-receiver-com-spec{data-element=LIN_IntLghtDimmingLvlFreeWhl_s, init-value=15}, required-interface=LIN_IntLghtDimmingLvlFreeWhl_s
      LIN_FogLightRear_ButtonStat_1: nonqueued-receiver-com-spec{data-element=LIN_FogLightRear_ButtonStat_1, init-value=3}, required-interface=LIN_FogLightRear_ButtonStat_1
      LIN_SpeedControlModeButtonStat: nonqueued-receiver-com-spec{data-element=LIN_SpeedControlModeButtonStat, init-value=3}, required-interface=LIN_SpeedControlModeButtonStat
      DiagInfoDLFW: nonqueued-receiver-com-spec{data-element=DiagInfoDLFW, init-value=0}, required-interface=DiagInfoDLFW
      LIN_FogLightRear_ButtonStat_2: nonqueued-receiver-com-spec{data-element=LIN_FogLightRear_ButtonStat_2, init-value=3}, required-interface=LIN_FogLightRear_ButtonStat_2
      LIN_StopButtonStatus: nonqueued-receiver-com-spec{data-element=LIN_StopButtonStatus, init-value=3}, required-interface=LIN_StopButtonStatus
      DiagInfoRCECS: nonqueued-receiver-com-spec{data-element=DiagInfoRCECS, init-value=0}, required-interface=DiagInfoRCECS
      LIN_LightMode_Status_1: nonqueued-receiver-com-spec{data-element=LIN_LightMode_Status_1, init-value=15}, required-interface=LIN_LightMode_Status_1
      LIN_WRUpButtonStatus: nonqueued-receiver-com-spec{data-element=LIN_WRUpButtonStatus, init-value=7}, required-interface=LIN_WRUpButtonStatus
      LIN_DifflockDeactivationBtn_st: nonqueued-receiver-com-spec{data-element=LIN_DifflockDeactivationBtn_st, init-value=3}, required-interface=LIN_DifflockDeactivationBtn_st
      LIN_IntLghtCenterBtnFreeWhl_s: nonqueued-receiver-com-spec{data-element=LIN_IntLghtCenterBtnFreeWhl_s, init-value=3}, required-interface=LIN_IntLghtCenterBtnFreeWhl_s
      SwitchDetectionResp1L5: nonqueued-receiver-com-spec{data-element=SwitchDetectionResp1L5, init-value=8 x 0}, required-interface=SwitchDetectionResp1L5
      FSP1DiagInfoL5: nonqueued-receiver-com-spec{data-element=FSP1DiagInfoL5, init-value=0}, required-interface=FSP1DiagInfoL5
      LIN_EscButtonMuddySiteStatus: nonqueued-receiver-com-spec{data-element=LIN_EscButtonMuddySiteStatus, init-value=3}, required-interface=LIN_EscButtonMuddySiteStatus
      FSP1SwitchStatusL5: nonqueued-receiver-com-spec{data-element=FSP1SwitchStatusL5, init-value=0}, required-interface=FSP1SwitchStatusL5
      SwitchDetectionNeeded1L4: nonqueued-receiver-com-spec{data-element=SwitchDetectionNeeded1L4, init-value=0}, required-interface=SwitchDetectionNeeded1L4
      LIN_AdjustButtonStatus: nonqueued-receiver-com-spec{data-element=LIN_AdjustButtonStatus, init-value=3}, required-interface=LIN_AdjustButtonStatus
      ResponseErrorDLFW: nonqueued-receiver-com-spec{data-element=ResponseErrorDLFW, init-value=0}, required-interface=ResponseErrorDLFW
      LIN_BlackPanelMode_ButtonStat: nonqueued-receiver-com-spec{data-element=LIN_BlackPanelMode_ButtonStat, init-value=3}, required-interface=LIN_BlackPanelMode_ButtonStat
      FSP1DiagInfoL4: nonqueued-receiver-com-spec{data-element=FSP1DiagInfoL4, init-value=0}, required-interface=FSP1DiagInfoL4
      LIN_FCWPushButton: nonqueued-receiver-com-spec{data-element=LIN_FCWPushButton, init-value=3}, required-interface=LIN_FCWPushButton
      ResponseErrorRCECS: nonqueued-receiver-com-spec{data-element=ResponseErrorRCECS, init-value=0}, required-interface=ResponseErrorRCECS
      DiagInfoELCP2: nonqueued-receiver-com-spec{data-element=DiagInfoELCP2, init-value=0}, required-interface=DiagInfoELCP2
      DiagInfoCCFW: nonqueued-receiver-com-spec{data-element=DiagInfoCCFW, init-value=0}, required-interface=DiagInfoCCFW
      DiagInfoILCP2: nonqueued-receiver-com-spec{data-element=DiagInfoILCP2, init-value=0}, required-interface=DiagInfoILCP2
      DiagInfoELCP1: nonqueued-receiver-com-spec{data-element=DiagInfoELCP1, init-value=0}, required-interface=DiagInfoELCP1
      LIN_BackLightDimming_Status: nonqueued-receiver-com-spec{data-element=LIN_BackLightDimming_Status, init-value=31}, required-interface=LIN_BackLightDimming_Status
      FSP1ResponseErrorL5: nonqueued-receiver-com-spec{data-element=FSP1ResponseErrorL5, init-value=0}, required-interface=FSP1ResponseErrorL5
      LIN_DRL_ButtonStatus: nonqueued-receiver-com-spec{data-element=LIN_DRL_ButtonStatus, init-value=3}, required-interface=LIN_DRL_ButtonStatus
      ResponseErrorELCP2: nonqueued-receiver-com-spec{data-element=ResponseErrorELCP2, init-value=0}, required-interface=ResponseErrorELCP2
      ResponseErrorCCFW: nonqueued-receiver-com-spec{data-element=ResponseErrorCCFW, init-value=0}, required-interface=ResponseErrorCCFW
      LIN_LevelingThumbwheel_stat: nonqueued-receiver-com-spec{data-element=LIN_LevelingThumbwheel_stat, init-value=31}, required-interface=LIN_LevelingThumbwheel_stat
      LIN_Offroad_ButtonStatus: nonqueued-receiver-com-spec{data-element=LIN_Offroad_ButtonStatus, init-value=3}, required-interface=LIN_Offroad_ButtonStatus
      LIN_FogLightFront_ButtonStat_2: nonqueued-receiver-com-spec{data-element=LIN_FogLightFront_ButtonStat_2, init-value=3}, required-interface=LIN_FogLightFront_ButtonStat_2
      LIN_RearWorkProjector_BtnStat: nonqueued-receiver-com-spec{data-element=LIN_RearWorkProjector_BtnStat, init-value=3}, required-interface=LIN_RearWorkProjector_BtnStat
      LIN_HeadLampUpDown_SwitchStatu: nonqueued-receiver-com-spec{data-element=LIN_HeadLampUpDown_SwitchStatu, init-value=7}, required-interface=LIN_HeadLampUpDown_SwitchStatu
      LIN_FogLightFront_ButtonStat_1: nonqueued-receiver-com-spec{data-element=LIN_FogLightFront_ButtonStat_1, init-value=3}, required-interface=LIN_FogLightFront_ButtonStat_1
      LIN_IntLghtMaxModeBtnPnl2_s: nonqueued-receiver-com-spec{data-element=LIN_IntLghtMaxModeBtnPnl2_s, init-value=3}, required-interface=LIN_IntLghtMaxModeBtnPnl2_s
      LIN_IntLghtRestModeBtnPnl2_s: nonqueued-receiver-com-spec{data-element=LIN_IntLghtRestModeBtnPnl2_s, init-value=3}, required-interface=LIN_IntLghtRestModeBtnPnl2_s
    23 x provide port:
      LIN_ACCOrCCIndication: nonqueued-sender-com-spec{data-element=LIN_ACCOrCCIndication, init-value=0}, provided-interface=LIN_ACCOrCCIndication
      LIN_M3_DeviceIndication: nonqueued-sender-com-spec{data-element=LIN_M3_DeviceIndication, init-value=0}, provided-interface=LIN_M3_DeviceIndication
      LIN_EscButtonMuddySiteDeviceIn: nonqueued-sender-com-spec{data-element=LIN_EscButtonMuddySiteDeviceIn, init-value=0}, provided-interface=LIN_EscButtonMuddySiteDeviceIn
      LIN_M1_DeviceIndication: nonqueued-sender-com-spec{data-element=LIN_M1_DeviceIndication, init-value=0}, provided-interface=LIN_M1_DeviceIndication
      LIN_ShortPulseMaxLength: nonqueued-sender-com-spec{data-element=LIN_ShortPulseMaxLength, init-value=0}, provided-interface=LIN_ShortPulseMaxLength
      LIN_FCW_DeviceIndication: nonqueued-sender-com-spec{data-element=LIN_FCW_DeviceIndication, init-value=0}, provided-interface=LIN_FCW_DeviceIndication
      LIN_DrivingLightPlus_Indicatio: nonqueued-sender-com-spec{data-element=LIN_DrivingLightPlus_Indicatio, init-value=0}, provided-interface=LIN_DrivingLightPlus_Indicatio
      LIN_RearFog_Indication: nonqueued-sender-com-spec{data-element=LIN_RearFog_Indication, init-value=0}, provided-interface=LIN_RearFog_Indication
      LIN_Offroad_Indication: nonqueued-sender-com-spec{data-element=LIN_Offroad_Indication, init-value=0}, provided-interface=LIN_Offroad_Indication
      LIN_LKS_DeviceIndication: nonqueued-sender-com-spec{data-element=LIN_LKS_DeviceIndication, init-value=0}, provided-interface=LIN_LKS_DeviceIndication
      LIN_Down_DeviceIndication: nonqueued-sender-com-spec{data-element=LIN_Down_DeviceIndication, init-value=0}, provided-interface=LIN_Down_DeviceIndication
      LIN_M2_DeviceIndication: nonqueued-sender-com-spec{data-element=LIN_M2_DeviceIndication, init-value=0}, provided-interface=LIN_M2_DeviceIndication
      LIN_ParkingLight_Indication: nonqueued-sender-com-spec{data-element=LIN_ParkingLight_Indication, init-value=0}, provided-interface=LIN_ParkingLight_Indication
      FSP1IndicationCmdL5: nonqueued-sender-com-spec{data-element=FSP1IndicationCmdL5, init-value=0}, provided-interface=FSP1IndicationCmdL5
      LIN_FrontFog_Indication: nonqueued-sender-com-spec{data-element=LIN_FrontFog_Indication, init-value=0}, provided-interface=LIN_FrontFog_Indication
      LIN_ASLIndication: nonqueued-sender-com-spec{data-element=LIN_ASLIndication, init-value=0}, provided-interface=LIN_ASLIndication
      LIN_DaytimeRunningLight_Indica: nonqueued-sender-com-spec{data-element=LIN_DaytimeRunningLight_Indica, init-value=0}, provided-interface=LIN_DaytimeRunningLight_Indica
      LIN_DifflockOnOff_Indication: nonqueued-sender-com-spec{data-element=LIN_DifflockOnOff_Indication, init-value=0}, provided-interface=LIN_DifflockOnOff_Indication
      LIN_RearWorkProjector_Indicati: nonqueued-sender-com-spec{data-element=LIN_RearWorkProjector_Indicati, init-value=0}, provided-interface=LIN_RearWorkProjector_Indicati
      FSP1IndicationCmdL4: nonqueued-sender-com-spec{data-element=FSP1IndicationCmdL4, init-value=0}, provided-interface=FSP1IndicationCmdL4
      LIN_Adjust_DeviceIndication: nonqueued-sender-com-spec{data-element=LIN_Adjust_DeviceIndication, init-value=0}, provided-interface=LIN_Adjust_DeviceIndication
      LIN_DrivingLight_Indication: nonqueued-sender-com-spec{data-element=LIN_DrivingLight_Indication, init-value=0}, provided-interface=LIN_DrivingLight_Indication
      LIN_Up_DeviceIndication: nonqueued-sender-com-spec{data-element=LIN_Up_DeviceIndication, init-value=0}, provided-interface=LIN_Up_DeviceIndication
    require port Debug_PVT_SCIM_Ctrl_LivingPullUp: nonqueued-receiver-com-spec{data-element=Debug_PVT_SCIM_Ctrl_LivingPullUp, init-value=0}, required-interface=Debug_PVT_SCIM_Ctrl_LivingPullUp_1
    require port Debug_PVT_SCIM_Ctrl_ParkedPullUp: nonqueued-receiver-com-spec{data-element=Debug_PVT_SCIM_Ctrl_ParkedPullUp, init-value=0}, required-interface=Debug_PVT_SCIM_Ctrl_ParkedPullUp_1
    6 x provide port:
      ABSInhibitRqstDenied: nonqueued-sender-com-spec{data-element=ABSInhibitRqstDenied, init-value=3}, provided-interface=ABSInhibitRqstDenied
      Debug_PVT_SCIM_RD_12VLivingVolt: nonqueued-sender-com-spec{data-element=Debug_PVT_SCIM_RD_12VLivingVolt, init-value=0}, provided-interface=Debug_PVT_SCIM_RD_12VLivingVolt_1
      Debug_PVT_SCIM_RD_12VParkedVolt: nonqueued-sender-com-spec{data-element=Debug_PVT_SCIM_RD_12VParkedVolt, init-value=0}, provided-interface=Debug_PVT_SCIM_RD_12VParkedVolt_1
      Debug_PVT_SCIM_RD_12VDCDCFault: nonqueued-sender-com-spec{data-element=Debug_PVT_SCIM_RD_12VDCDCFault, init-value=0}, provided-interface=Debug_PVT_SCIM_RD_12VDCDCFault_1
      Debug_PVT_SCIM_RD_12VDCDCVolt: nonqueued-sender-com-spec{data-element=Debug_PVT_SCIM_RD_12VDCDCVolt, init-value=0}, provided-interface=Debug_PVT_SCIM_RD_12VDCDCVolt_1
      Debug_PVT_SCIM_RD_VBAT: nonqueued-sender-com-spec{data-element=Debug_PVT_SCIM_RD_VBAT, init-value=0}, provided-interface=Debug_PVT_SCIM_RD_VBAT_1
    15 x require port:
      Debug_PVT_SCIM_Ctrl_WLS2Freq: nonqueued-receiver-com-spec{data-element=Debug_PVT_SCIM_Ctrl_WLS2Freq, init-value=0}, required-interface=Debug_PVT_SCIM_Ctrl_WLS2Freq_1
      Debug_PVT_SCIM_Ctrl_WLS3: nonqueued-receiver-com-spec{data-element=Debug_PVT_SCIM_Ctrl_WLS3, init-value=0}, required-interface=Debug_PVT_SCIM_Ctrl_WLS3_1
      Debug_PVT_SCIM_Ctrl_WLS2Duty: nonqueued-receiver-com-spec{data-element=Debug_PVT_SCIM_Ctrl_WLS2Duty, init-value=0}, required-interface=Debug_PVT_SCIM_Ctrl_WLS2Duty_1
      Debug_PVT_SCIM_Ctrl_WLS1_Duty: nonqueued-receiver-com-spec{data-element=Debug_PVT_SCIM_Ctrl_WLS1_Duty, init-value=0}, required-interface=Debug_PVT_SCIM_Ctrl_WLS1_Duty_1
      Debug_PVT_SCIM_Ctrl_WHS1: nonqueued-receiver-com-spec{data-element=Debug_PVT_SCIM_Ctrl_WHS1, init-value=0}, required-interface=Debug_PVT_SCIM_Ctrl_WHS1_1
      Debug_PVT_SCIM_Ctrl_WHS1_Freq: nonqueued-receiver-com-spec{data-element=Debug_PVT_SCIM_Ctrl_WHS1_Freq, init-value=0}, required-interface=Debug_PVT_SCIM_Ctrl_WHS1_Freq_1
      Debug_PVT_SCIM_Ctrl_WLS3Duty: nonqueued-receiver-com-spec{data-element=Debug_PVT_SCIM_Ctrl_WLS3Duty, init-value=0}, required-interface=Debug_PVT_SCIM_Ctrl_WLS3Duty_1
      Debug_PVT_SCIM_Ctrl_WHS1_Duty: nonqueued-receiver-com-spec{data-element=Debug_PVT_SCIM_Ctrl_WHS1_Duty, init-value=0}, required-interface=Debug_PVT_SCIM_Ctrl_WHS1_Duty_1
      Debug_PVT_SCIM_Ctrl_WLS1_Freq: nonqueued-receiver-com-spec{data-element=Debug_PVT_SCIM_Ctrl_WLS1_Freq, init-value=0}, required-interface=Debug_PVT_SCIM_Ctrl_WLS1_Freq_1
      Debug_PVT_SCIM_Ctrl_WLS3Freq: nonqueued-receiver-com-spec{data-element=Debug_PVT_SCIM_Ctrl_WLS3Freq, init-value=0}, required-interface=Debug_PVT_SCIM_Ctrl_WLS3Freq_1
      Debug_PVT_SCIM_Ctrl_WHS2: nonqueued-receiver-com-spec{data-element=Debug_PVT_SCIM_Ctrl_WHS2, init-value=0}, required-interface=Debug_PVT_SCIM_Ctrl_WHS2_1
      Debug_PVT_SCIM_Ctrl_WLS2: nonqueued-receiver-com-spec{data-element=Debug_PVT_SCIM_Ctrl_WLS2, init-value=0}, required-interface=Debug_PVT_SCIM_Ctrl_WLS2_1
      Debug_PVT_SCIM_Ctrl_WHS2_Freq: nonqueued-receiver-com-spec{data-element=Debug_PVT_SCIM_Ctrl_WHS2_Freq, init-value=0}, required-interface=Debug_PVT_SCIM_Ctrl_WHS2_Freq_1
      Debug_PVT_SCIM_Ctrl_WLS1: nonqueued-receiver-com-spec{data-element=Debug_PVT_SCIM_Ctrl_WLS1, init-value=0}, required-interface=Debug_PVT_SCIM_Ctrl_WLS1_1
      Debug_PVT_SCIM_Ctrl_WHS2_Duty: nonqueued-receiver-com-spec{data-element=Debug_PVT_SCIM_Ctrl_WHS2_Duty, init-value=0}, required-interface=Debug_PVT_SCIM_Ctrl_WHS2_Duty_1
    20 x provide port:
      Debug_PVT_SCIM_RD_WLS1_Duty: nonqueued-sender-com-spec{data-element=Debug_PVT_SCIM_RD_WLS1_Duty, init-value=0}, provided-interface=Debug_PVT_SCIM_RD_WLS1_Duty_1
      Debug_PVT_SCIM_RD_WLS3_Freq: nonqueued-sender-com-spec{data-element=Debug_PVT_SCIM_RD_WLS3_Freq, init-value=0}, provided-interface=Debug_PVT_SCIM_RD_WLS3_Freq_1
      Debug_PVT_SCIM_RD_WHS1_Volt: nonqueued-sender-com-spec{data-element=Debug_PVT_SCIM_RD_WHS1_Volt, init-value=0}, provided-interface=Debug_PVT_SCIM_RD_WHS1_Volt_1
      Debug_PVT_SCIM_RD_WLS2_Fault: nonqueued-sender-com-spec{data-element=Debug_PVT_SCIM_RD_WLS2_Fault, init-value=0}, provided-interface=Debug_PVT_SCIM_RD_WLS2_Fault_1
      Debug_PVT_SCIM_RD_WLS1_Volt: nonqueued-sender-com-spec{data-element=Debug_PVT_SCIM_RD_WLS1_Volt, init-value=0}, provided-interface=Debug_PVT_SCIM_RD_WLS1_Volt_1
      Debug_PVT_SCIM_RD_WHS2_Volt: nonqueued-sender-com-spec{data-element=Debug_PVT_SCIM_RD_WHS2_Volt, init-value=0}, provided-interface=Debug_PVT_SCIM_RD_WHS2_Volt_1
      Debug_PVT_SCIM_RD_WHS1_Duty: nonqueued-sender-com-spec{data-element=Debug_PVT_SCIM_RD_WHS1_Duty, init-value=0}, provided-interface=Debug_PVT_SCIM_RD_WHS1_Duty_1
      Debug_PVT_SCIM_RD_WLS2_Volt: nonqueued-sender-com-spec{data-element=Debug_PVT_SCIM_RD_WLS2_Volt, init-value=0}, provided-interface=Debug_PVT_SCIM_RD_WLS2_Volt_1
      Debug_PVT_SCIM_RD_WLS1_Fault: nonqueued-sender-com-spec{data-element=Debug_PVT_SCIM_RD_WLS1_Fault, init-value=0}, provided-interface=Debug_PVT_SCIM_RD_WLS1_Fault_1
      Debug_PVT_SCIM_RD_WLS2_Freq: nonqueued-sender-com-spec{data-element=Debug_PVT_SCIM_RD_WLS2_Freq, init-value=0}, provided-interface=Debug_PVT_SCIM_RD_WLS2_Freq_1
      Debug_PVT_SCIM_RD_WHS2_Duty: nonqueued-sender-com-spec{data-element=Debug_PVT_SCIM_RD_WHS2_Duty, init-value=0}, provided-interface=Debug_PVT_SCIM_RD_WHS2_Duty_1
      Debug_PVT_SCIM_RD_WHS1_Freq: nonqueued-sender-com-spec{data-element=Debug_PVT_SCIM_RD_WHS1_Freq, init-value=0}, provided-interface=Debug_PVT_SCIM_RD_WHS1_Freq_1
      Debug_PVT_SCIM_RD_WLS2_Duty: nonqueued-sender-com-spec{data-element=Debug_PVT_SCIM_RD_WLS2_Duty, init-value=0}, provided-interface=Debug_PVT_SCIM_RD_WLS2_Duty_1
      Debug_PVT_SCIM_RD_WHS1_Fault: nonqueued-sender-com-spec{data-element=Debug_PVT_SCIM_RD_WHS1_Fault, init-value=0}, provided-interface=Debug_PVT_SCIM_RD_WHS1_Fault_1
      Debug_PVT_SCIM_RD_WHS2_Freq: nonqueued-sender-com-spec{data-element=Debug_PVT_SCIM_RD_WHS2_Freq, init-value=0}, provided-interface=Debug_PVT_SCIM_RD_WHS2_Freq_1
      Debug_PVT_SCIM_RD_WLS3_Duty: nonqueued-sender-com-spec{data-element=Debug_PVT_SCIM_RD_WLS3_Duty, init-value=0}, provided-interface=Debug_PVT_SCIM_RD_WLS3_Duty_1
      Debug_PVT_SCIM_RD_WHS2_Fault: nonqueued-sender-com-spec{data-element=Debug_PVT_SCIM_RD_WHS2_Fault, init-value=0}, provided-interface=Debug_PVT_SCIM_RD_WHS2_Fault_1
      Debug_PVT_SCIM_RD_WLS3_Fault: nonqueued-sender-com-spec{data-element=Debug_PVT_SCIM_RD_WLS3_Fault, init-value=0}, provided-interface=Debug_PVT_SCIM_RD_WLS3_Fault_1
      Debug_PVT_SCIM_RD_WLS1_Freq: nonqueued-sender-com-spec{data-element=Debug_PVT_SCIM_RD_WLS1_Freq, init-value=0}, provided-interface=Debug_PVT_SCIM_RD_WLS1_Freq_1
      Debug_PVT_SCIM_RD_WLS3_Volt: nonqueued-sender-com-spec{data-element=Debug_PVT_SCIM_RD_WLS3_Volt, init-value=0}, provided-interface=Debug_PVT_SCIM_RD_WLS3_Volt_1
    9 x require port:
      Debug_PVT_SCIM_Ctrl_12VDCDC: nonqueued-receiver-com-spec{data-element=Debug_PVT_SCIM_Ctrl_12VDCDC, init-value=0}, required-interface=Debug_PVT_SCIM_Ctrl_12VDCDC_1
      Debug_PVT_SCIM_Ctrl_12VParked: nonqueued-receiver-com-spec{data-element=Debug_PVT_SCIM_Ctrl_12VParked, init-value=0}, required-interface=Debug_PVT_SCIM_Ctrl_12VParked_1
      Debug_PVT_SCIM_Ctrl_12VLiving: nonqueued-receiver-com-spec{data-element=Debug_PVT_SCIM_Ctrl_12VLiving, init-value=0}, required-interface=Debug_PVT_SCIM_Ctrl_12VLiving_1
      Debug_PVT_PEPS_VDSI_Ctrl_P: nonqueued-receiver-com-spec{data-element=Debug_PVT_PEPS_VDSI_Ctrl, filter=data-filter-type=ALWAYS, init-value=0}, required-interface=Debug_PVT_PEPS_VDSI_Ctrl
      Debug_PVT_PEPS_GainP2_Ctrl_P: nonqueued-receiver-com-spec{data-element=Debug_PVT_PEPS_GainP2_Ctrl, filter=data-filter-type=ALWAYS, init-value=0}, required-interface=Debug_PVT_PEPS_GainP2_Ctrl
      Debug_PVT_PEPS_GainP3_Ctrl_P: nonqueued-receiver-com-spec{data-element=Debug_PVT_PEPS_GainP3_Ctrl, filter=data-filter-type=ALWAYS, init-value=0}, required-interface=Debug_PVT_PEPS_GainP3_Ctrl
      Debug_PVT_PEPS_GainP1_Ctrl_P: nonqueued-receiver-com-spec{data-element=Debug_PVT_PEPS_GainP1_Ctrl, filter=data-filter-type=ALWAYS, init-value=0}, required-interface=Debug_PVT_PEPS_GainP1_Ctrl
      Debug_PVT_PEPS_GainP4_Ctrl_P: nonqueued-receiver-com-spec{data-element=Debug_PVT_PEPS_GainP4_Ctrl, filter=data-filter-type=ALWAYS, init-value=0}, required-interface=Debug_PVT_PEPS_GainP4_Ctrl
      Debug_PVT_PEPS_Ant_Ctrl_P: nonqueued-receiver-com-spec{data-element=Debug_PVT_PEPS_Ant_Ctrl, filter=data-filter-type=ALWAYS, init-value=0}, required-interface=Debug_PVT_PEPS_Ant_Ctrl
    11 x provide port:
      Debug_PVT_PEPS_P4_MaxRSSI_P: nonqueued-sender-com-spec{data-element=Debug_PVT_PEPS_P4_MaxRSSI, init-value=0}, provided-interface=Debug_PVT_PEPS_P4_MaxRSSI
      Debug_PVT_PEPS_GainP1_stat_P: nonqueued-sender-com-spec{data-element=Debug_PVT_PEPS_GainP1_stat, init-value=0}, provided-interface=Debug_PVT_PEPS_GainP1_stat
      Debug_PVT_PEPS_P2_MaxRSSI_P: nonqueued-sender-com-spec{data-element=Debug_PVT_PEPS_P2_MaxRSSI, init-value=0}, provided-interface=Debug_PVT_PEPS_P2_MaxRSSI
      Debug_PVT_PEPS_P3_MaxRSSI_P: nonqueued-sender-com-spec{data-element=Debug_PVT_PEPS_P3_MaxRSSI, init-value=0}, provided-interface=Debug_PVT_PEPS_P3_MaxRSSI
      Debug_PVT_PEPS_AntCtrl_stat_P: nonqueued-sender-com-spec{data-element=Debug_PVT_PEPS_AntCtrl_stat, init-value=0}, provided-interface=Debug_PVT_PEPS_AntCtrl_stat
      Debug_PVT_PEPS_GainP3_stat_P: nonqueued-sender-com-spec{data-element=Debug_PVT_PEPS_GainP3_stat, init-value=0}, provided-interface=Debug_PVT_PEPS_GainP3_stat
      Debug_PVT_PEPS_GainP4_stat_P: nonqueued-sender-com-spec{data-element=Debug_PVT_PEPS_GainP4_stat, init-value=0}, provided-interface=Debug_PVT_PEPS_GainP4_stat
      Debug_PVT_PEPS_VDSI_stat_P: nonqueued-sender-com-spec{data-element=Debug_PVT_PEPS_VDSI_stat, init-value=0}, provided-interface=Debug_PVT_PEPS_VDSI_stat
      Debug_PVT_PEPS_GainP2_stat_P: nonqueued-sender-com-spec{data-element=Debug_PVT_PEPS_GainP2_stat, init-value=0}, provided-interface=Debug_PVT_PEPS_GainP2_stat
      Debug_PVT_PEPS_P1_MaxRSSI_P: nonqueued-sender-com-spec{data-element=Debug_PVT_PEPS_P1_MaxRSSI, init-value=0}, provided-interface=Debug_PVT_PEPS_P1_MaxRSSI
      Debug_PVT_PEPS_Logic_stat_P: nonqueued-sender-com-spec{data-element=Debug_PVT_PEPS_Logic_stat, init-value=0}, provided-interface=Debug_PVT_PEPS_Logic_stat
    9 x component:
      TestLin: type=TestLin
      PVTApp_Do12VInterface: type=PVTApp_Do12VInterface
      PVTApp_AdiInterfaces: type=PVTApp_AdiInterfaces
      PVTApp_DobhsCtrlInterface: type=PVTApp_DobhsCtrlInterface
      IOHWAB: type=IoHwAb
      PVTApp_DowhsDowlsInterface: type=PVTApp_DowhsDowlsInterface
      CDD_LFIC: type=CDD_LFIC
      CDD_RFIC: type=CDD_RFIC
      PEPS: type=PEPS
    delegate TestLin.SwitchDetectionNeeded2L3 <-> outer port SwitchDetectionNeeded2L3
    delegate TestLin.FSP1SwitchStatusL3 <-> outer port FSP1SwitchStatusL3
    delegate TestLin.FSP2SwitchStatusL3 <-> outer port FSP2SwitchStatusL3
    delegate TestLin.FSP2DiagInfoL3 <-> outer port FSP2DiagInfoL3
    delegate TestLin.FSP1ResponseErrorL3 <-> outer port FSP1ResponseErrorL3
    delegate TestLin.LIN_TCP_KnobPostionStatus <-> outer port LIN_TCP_KnobPostionStatus
    delegate TestLin.SwitchDetectionNeeded1L3 <-> outer port SwitchDetectionNeeded1L3
    delegate TestLin.FSP1DiagInfoL3 <-> outer port FSP1DiagInfoL3
    delegate TestLin.SwitchDetectionResp2L3 <-> outer port SwitchDetectionResp2L3
    delegate TestLin.SwitchDetectionResp1L3 <-> outer port SwitchDetectionResp1L3
    delegate TestLin.ResponseErrorTCP <-> outer port ResponseErrorTCP
    delegate TestLin.LIN_TCP_ABS_ButtonStatus <-> outer port LIN_TCP_ABS_ButtonStatus
    delegate TestLin.LIN_TCP_TCS_ButtonStatus <-> outer port LIN_TCP_TCS_ButtonStatus
    delegate TestLin.FSP2ResponseErrorL3 <-> outer port FSP2ResponseErrorL3
    delegate TestLin.DiagInfoTCP <-> outer port DiagInfoTCP
    delegate TestLin.LIN_TCP_ATC_ButtonStatus <-> outer port LIN_TCP_ATC_ButtonStatus
    delegate TestLin.LIN_TCP_ESC_ButtonStatus <-> outer port LIN_TCP_ESC_ButtonStatus
    delegate TestLin.ATC_Indication <-> outer port ATC_Indication
    delegate TestLin.ABS_Indication <-> outer port ABS_Indication
    delegate TestLin.ESC_Indication <-> outer port ESC_Indication
    delegate TestLin.FSP1IndicationCmdL3 <-> outer port FSP1IndicationCmdL3
    delegate TestLin.TCS_Indication <-> outer port TCS_Indication
    delegate TestLin.FSP2IndicationCmdL3 <-> outer port FSP2IndicationCmdL3
    delegate PVTApp_DobhsCtrlInterface.Debug_PVT_SCIM_Ctrl_BHS3_1 <-> outer port Debug_PVT_SCIM_Ctrl_BHS3
    delegate PVTApp_DobhsCtrlInterface.Debug_PVT_SCIM_Ctrl_BHS2_1 <-> outer port Debug_PVT_SCIM_Ctrl_BHS2
    delegate PVTApp_DobhsCtrlInterface.Debug_PVT_SCIM_Ctrl_BHS1_1 <-> outer port Debug_PVT_SCIM_Ctrl_BHS1
    delegate PVTApp_DobhsCtrlInterface.Debug_PVT_SCIM_Ctrl_BHS4_1 <-> outer port Debug_PVT_SCIM_Ctrl_BHS4
    delegate PVTApp_DobhsCtrlInterface.Debug_PVT_SCIM_RD_BHS3_Volt_1 <-> outer port Debug_PVT_SCIM_RD_BHS3_Volt
    delegate PVTApp_DobhsCtrlInterface.Debug_PVT_SCIM_RD_BHS1_Volt_1 <-> outer port Debug_PVT_SCIM_RD_BHS1_Volt
    delegate PVTApp_DobhsCtrlInterface.Debug_PVT_SCIM_RD_BHS3_Fault_1 <-> outer port Debug_PVT_SCIM_RD_BHS3_Fault
    delegate PVTApp_DobhsCtrlInterface.Debug_PVT_SCIM_RD_BHS1_Fault_1 <-> outer port Debug_PVT_SCIM_RD_BHS1_Fault
    delegate PVTApp_DobhsCtrlInterface.Debug_PVT_SCIM_RD_BHS2_Fault_1 <-> outer port Debug_PVT_SCIM_RD_BHS2_Fault
    delegate PVTApp_DobhsCtrlInterface.Debug_PVT_SCIM_RD_BHS2_Volt_1 <-> outer port Debug_PVT_SCIM_RD_BHS2_Volt
    delegate PVTApp_DobhsCtrlInterface.Debug_PVT_SCIM_RD_BHS4_Fault_1 <-> outer port Debug_PVT_SCIM_RD_BHS4_Fault
    delegate PVTApp_DobhsCtrlInterface.Debug_PVT_SCIM_RD_BHS4_Volt_1 <-> outer port Debug_PVT_SCIM_RD_BHS4_Volt
    delegate PVTApp_AdiInterfaces.Debug_PVT_SCIM_Ctrl_DaiPullUp_1 <-> outer port Debug_PVT_SCIM_Ctrl_DaiPullUp
    delegate PVTApp_AdiInterfaces.Debug_PVT_SCIM_RD_ADI09_1 <-> outer port Debug_PVT_SCIM_RD_ADI09
    delegate PVTApp_AdiInterfaces.Debug_PVT_SCIM_RD_ADI16_1 <-> outer port Debug_PVT_SCIM_RD_ADI16
    delegate PVTApp_AdiInterfaces.Debug_PVT_SCIM_RD_ADI07_1 <-> outer port Debug_PVT_SCIM_RD_ADI07
    delegate PVTApp_AdiInterfaces.Debug_PVT_SCIM_RD_ADI02_1 <-> outer port Debug_PVT_SCIM_RD_ADI02
    delegate PVTApp_AdiInterfaces.Debug_PVT_SCIM_RD_DAI1_1 <-> outer port Debug_PVT_SCIM_RD_DAI1
    delegate PVTApp_AdiInterfaces.Debug_PVT_SCIM_RD_ADI10_1 <-> outer port Debug_PVT_SCIM_RD_ADI10
    delegate PVTApp_AdiInterfaces.Debug_PVT_SCIM_RD_ADI06_1 <-> outer port Debug_PVT_SCIM_RD_ADI06
    delegate PVTApp_AdiInterfaces.Debug_PVT_SCIM_RD_ADI01_1 <-> outer port Debug_PVT_SCIM_RD_ADI01
    delegate PVTApp_AdiInterfaces.Debug_PVT_SCIM_RD_ADI03_1 <-> outer port Debug_PVT_SCIM_RD_ADI03
    delegate PVTApp_AdiInterfaces.Debug_PVT_SCIM_RD_ADI11_1 <-> outer port Debug_PVT_SCIM_RD_ADI11
    delegate PVTApp_AdiInterfaces.Debug_PVT_SCIM_RD_ADI14_1 <-> outer port Debug_PVT_SCIM_RD_ADI14
    delegate PVTApp_AdiInterfaces.Debug_PVT_SCIM_RD_ADI13_1 <-> outer port Debug_PVT_SCIM_RD_ADI13
    delegate PVTApp_AdiInterfaces.Debug_PVT_SCIM_RD_ADI04_1 <-> outer port Debug_PVT_SCIM_RD_ADI04
    delegate PVTApp_AdiInterfaces.Debug_PVT_SCIM_RD_ADI12_1 <-> outer port Debug_PVT_SCIM_RD_ADI12
    delegate PVTApp_AdiInterfaces.Debug_PVT_SCIM_RD_ADI15_1 <-> outer port Debug_PVT_SCIM_RD_ADI15
    delegate PVTApp_AdiInterfaces.Debug_PVT_SCIM_RD_ADI05_1 <-> outer port Debug_PVT_SCIM_RD_ADI05
    delegate PVTApp_AdiInterfaces.Debug_PVT_SCIM_RD_DAI2_1 <-> outer port Debug_PVT_SCIM_RD_DAI2
    delegate PVTApp_AdiInterfaces.Debug_PVT_SCIM_RD_ADI08_1 <-> outer port Debug_PVT_SCIM_RD_ADI08
    delegate TestLin.LIN_BunkH2RoofhatchCloseBtn_St <-> outer port LIN_BunkH2RoofhatchCloseBtn_St
    delegate TestLin.LIN_BunkH2LockButtonStatus <-> outer port LIN_BunkH2LockButtonStatus
    delegate TestLin.LIN_AlmClkSetCurAlm_rqst_sg <-> outer port LIN_AlmClkSetCurAlm_rqst_sg
    delegate TestLin.LIN_BunkH2IntLightIncBtn_stat <-> outer port LIN_BunkH2IntLightIncBtn_stat
    delegate TestLin.LIN_BunkH2Fade_ButtonStatus <-> outer port LIN_BunkH2Fade_ButtonStatus
    delegate TestLin.SwitchDetectionNeeded1L1 <-> outer port SwitchDetectionNeeded1L1
    delegate TestLin.LIN_BunkH2PowerWinOpenPSBtn_st <-> outer port LIN_BunkH2PowerWinOpenPSBtn_st
    delegate TestLin.LIN_IntLghtDimmingLvlDecBtn_s <-> outer port LIN_IntLghtDimmingLvlDecBtn_s
    delegate TestLin.LIN_IntLghtDimmingLvlIncBtn_s <-> outer port LIN_IntLghtDimmingLvlIncBtn_s
    delegate TestLin.ResponseErrorLECM2 <-> outer port ResponseErrorLECM2
    delegate TestLin.LIN_BunkH2PHTi_rqs_sg <-> outer port LIN_BunkH2PHTi_rqs_sg
    delegate TestLin.ResponseErrorLECMBasic <-> outer port ResponseErrorLECMBasic
    delegate TestLin.LIN_BunkH2VolumeDown_ButtonSta <-> outer port LIN_BunkH2VolumeDown_ButtonSta
    delegate TestLin.LIN_BunkH2IntLightDecBtn_stat <-> outer port LIN_BunkH2IntLightDecBtn_stat
    delegate TestLin.FSP2DiagInfoL1 <-> outer port FSP2DiagInfoL1
    delegate TestLin.LIN_BunkBAudioOnOff_ButtonStat <-> outer port LIN_BunkBAudioOnOff_ButtonStat
    delegate TestLin.DiagInfoLECM2 <-> outer port DiagInfoLECM2
    delegate TestLin.SwitchDetectionNeeded2L1 <-> outer port SwitchDetectionNeeded2L1
    delegate TestLin.DiagInfoLECMBasic <-> outer port DiagInfoLECMBasic
    delegate TestLin.LIN_BunkBVolumeDown_ButtonStat <-> outer port LIN_BunkBVolumeDown_ButtonStat
    delegate TestLin.LIN_IntLghtModeSelrFreeWheel_s <-> outer port LIN_IntLghtModeSelrFreeWheel_s
    delegate TestLin.LIN_BunkH2OnOFF_ButtonStatus <-> outer port LIN_BunkH2OnOFF_ButtonStatus
    delegate TestLin.FSP1ResponseErrorL1 <-> outer port FSP1ResponseErrorL1
    delegate TestLin.LIN_BunkH2VolumeUp_ButtonStatu <-> outer port LIN_BunkH2VolumeUp_ButtonStatu
    delegate TestLin.ResponseErrorILCP1 <-> outer port ResponseErrorILCP1
    delegate TestLin.LIN_BunkH2Phone_ButtonStatus <-> outer port LIN_BunkH2Phone_ButtonStatus
    delegate TestLin.FSP2ResponseErrorL1 <-> outer port FSP2ResponseErrorL1
    delegate TestLin.LIN_BunkH2PowerWinCloseDSBtn_s <-> outer port LIN_BunkH2PowerWinCloseDSBtn_s
    delegate TestLin.LIN_BunkH2PowerWinOpenDSBtn_st <-> outer port LIN_BunkH2PowerWinOpenDSBtn_st
    delegate TestLin.LIN_DoorAutoFuncBtn_stat <-> outer port LIN_DoorAutoFuncBtn_stat
    delegate TestLin.LIN_BunkH2TempDec_ButtonStatus <-> outer port LIN_BunkH2TempDec_ButtonStatus
    delegate TestLin.LIN_BunkBVolumeUp_ButtonStat <-> outer port LIN_BunkBVolumeUp_ButtonStat
    delegate TestLin.LIN_BunkBIntLightActvnBtn_stat <-> outer port LIN_BunkBIntLightActvnBtn_stat
    delegate TestLin.LIN_BunkH2PowerWinClosePSBtn_s <-> outer port LIN_BunkH2PowerWinClosePSBtn_s
    delegate TestLin.LIN_BunkBParkHeater_ButtonStat <-> outer port LIN_BunkBParkHeater_ButtonStat
    delegate TestLin.LIN_BunkH2ParkHeater_ButtonSta <-> outer port LIN_BunkH2ParkHeater_ButtonSta
    delegate TestLin.LIN_BunkBTempInc_ButtonStat <-> outer port LIN_BunkBTempInc_ButtonStat
    delegate TestLin.LIN_BunkH2AudioOnOff_ButtonSta <-> outer port LIN_BunkH2AudioOnOff_ButtonSta
    delegate TestLin.SwitchDetectionResp2L1 <-> outer port SwitchDetectionResp2L1
    delegate TestLin.LIN_BunkH2IntLightActvnBtn_sta <-> outer port LIN_BunkH2IntLightActvnBtn_sta
    delegate TestLin.LIN_BunkH2RoofhatchOpenBtn_Sta <-> outer port LIN_BunkH2RoofhatchOpenBtn_Sta
    delegate TestLin.SwitchDetectionResp1L1 <-> outer port SwitchDetectionResp1L1
    delegate TestLin.FSP1DiagInfoL1 <-> outer port FSP1DiagInfoL1
    delegate TestLin.DiagInfoILCP1 <-> outer port DiagInfoILCP1
    delegate TestLin.LIN_BunkBTempDec_ButtonStat <-> outer port LIN_BunkBTempDec_ButtonStat
    delegate TestLin.LIN_BunkH2TempInc_ButtonStatus <-> outer port LIN_BunkH2TempInc_ButtonStatus
    delegate TestLin.LIN_IntLightMaxModeInd_cmd <-> outer port LIN_IntLightMaxModeInd_cmd
    delegate TestLin.LIN_AlmClkCurAlarm_stat_sg <-> outer port LIN_AlmClkCurAlarm_stat_sg
    delegate TestLin.LIN_DoorAutoFuncInd_cmd <-> outer port LIN_DoorAutoFuncInd_cmd
    delegate TestLin.LIN_IntLightNightModeInd_cmd <-> outer port LIN_IntLightNightModeInd_cmd
    delegate TestLin.LIN_IntLightRestingModeInd_cmd <-> outer port LIN_IntLightRestingModeInd_cmd
    delegate TestLin.LIN_AudioVolumeIndicationCmd <-> outer port LIN_AudioVolumeIndicationCmd
    delegate TestLin.LIN_IntLghtOffModeInd_cmd <-> outer port LIN_IntLghtOffModeInd_cmd
    delegate TestLin.FSP2IndicationCmdL1 <-> outer port FSP2IndicationCmdL1
    delegate TestLin.LIN_PhoneButtonIndication_cmd <-> outer port LIN_PhoneButtonIndication_cmd
    delegate TestLin.LIN_AudioSystemStatus <-> outer port LIN_AudioSystemStatus
    delegate TestLin.LIN_BTStatus <-> outer port LIN_BTStatus
    delegate TestLin.DoorLock_stat <-> outer port DoorLock_stat
    delegate TestLin.LIN_IntLghtLvlIndScaled_cmd <-> outer port LIN_IntLghtLvlIndScaled_cmd
    delegate TestLin.LIN_IntLghtModeInd_cmd_sg <-> outer port LIN_IntLghtModeInd_cmd_sg
    delegate TestLin.FSP3ResponseErrorL2 <-> outer port FSP3ResponseErrorL2
    delegate TestLin.FSP1SwitchStatusL2 <-> outer port FSP1SwitchStatusL2
    delegate TestLin.SwitchDetectionResp1L2 <-> outer port SwitchDetectionResp1L2
    delegate TestLin.SwitchDetectionNeeded2L2 <-> outer port SwitchDetectionNeeded2L2
    delegate TestLin.FSP3SwitchStatusL2 <-> outer port FSP3SwitchStatusL2
    delegate TestLin.FSP3DiagInfoL2 <-> outer port FSP3DiagInfoL2
    delegate TestLin.FSP1DiagInfoL2 <-> outer port FSP1DiagInfoL2
    delegate TestLin.FSP4ResponseErrorL2 <-> outer port FSP4ResponseErrorL2
    delegate TestLin.FSP4DiagInfoL2 <-> outer port FSP4DiagInfoL2
    delegate TestLin.FSP2DiagInfoL2 <-> outer port FSP2DiagInfoL2
    delegate TestLin.SwitchDetectionResp4L2 <-> outer port SwitchDetectionResp4L2
    delegate TestLin.FSP4SwitchStatusL2 <-> outer port FSP4SwitchStatusL2
    delegate TestLin.FSP1ResponseErrorL2 <-> outer port FSP1ResponseErrorL2
    delegate TestLin.SwitchDetectionResp2L2 <-> outer port SwitchDetectionResp2L2
    delegate TestLin.FSP2SwitchStatusL2 <-> outer port FSP2SwitchStatusL2
    delegate TestLin.SwitchDetectionNeeded1L2 <-> outer port SwitchDetectionNeeded1L2
    delegate TestLin.FSP2ResponseErrorL2 <-> outer port FSP2ResponseErrorL2
    delegate TestLin.SwitchDetectionNeeded3L2 <-> outer port SwitchDetectionNeeded3L2
    delegate TestLin.SwitchDetectionResp3L2 <-> outer port SwitchDetectionResp3L2
    delegate TestLin.SwitchDetectionNeeded4L2 <-> outer port SwitchDetectionNeeded4L2
    delegate TestLin.FSP3IndicationCmdL2 <-> outer port FSP3IndicationCmdL2
    delegate TestLin.FSP1IndicationCmdL2 <-> outer port FSP1IndicationCmdL2
    delegate TestLin.FSP4IndicationCmdL2 <-> outer port FSP4IndicationCmdL2
    delegate TestLin.FSP2IndicationCmdL2 <-> outer port FSP2IndicationCmdL2
    delegate TestLin.ResponseErrorELCP1 <-> outer port ResponseErrorELCP1
    delegate TestLin.SwitchDetectionNeeded1L5 <-> outer port SwitchDetectionNeeded1L5
    delegate TestLin.LIN_WRDownButtonStatus <-> outer port LIN_WRDownButtonStatus
    delegate TestLin.FSP1SwitchStatusL4 <-> outer port FSP1SwitchStatusL4
    delegate TestLin.LIN_IntLghtNightModeBt2_s <-> outer port LIN_IntLghtNightModeBt2_s
    delegate TestLin.ResponseErrorILCP2 <-> outer port ResponseErrorILCP2
    delegate TestLin.FSP1ResponseErrorL4 <-> outer port FSP1ResponseErrorL4
    delegate TestLin.LIN_DifflockMode_Wheelstatus <-> outer port LIN_DifflockMode_Wheelstatus
    delegate TestLin.LIN_LKSPushButton <-> outer port LIN_LKSPushButton
    delegate TestLin.LIN_LightMode_Status_2 <-> outer port LIN_LightMode_Status_2
    delegate TestLin.LIN_SpeedControlModeWheelStat <-> outer port LIN_SpeedControlModeWheelStat
    delegate TestLin.LIN_BackButtonStatus <-> outer port LIN_BackButtonStatus
    delegate TestLin.LIN_MemButtonStatus <-> outer port LIN_MemButtonStatus
    delegate TestLin.SwitchDetectionResp1L4 <-> outer port SwitchDetectionResp1L4
    delegate TestLin.LIN_SelectButtonStatus <-> outer port LIN_SelectButtonStatus
    delegate TestLin.LIN_IntLghtDimmingLvlFreeWhl_s <-> outer port LIN_IntLghtDimmingLvlFreeWhl_s
    delegate TestLin.LIN_FogLightRear_ButtonStat_1 <-> outer port LIN_FogLightRear_ButtonStat_1
    delegate TestLin.LIN_SpeedControlModeButtonStat <-> outer port LIN_SpeedControlModeButtonStat
    delegate TestLin.DiagInfoDLFW <-> outer port DiagInfoDLFW
    delegate TestLin.LIN_FogLightRear_ButtonStat_2 <-> outer port LIN_FogLightRear_ButtonStat_2
    delegate TestLin.LIN_StopButtonStatus <-> outer port LIN_StopButtonStatus
    delegate TestLin.DiagInfoRCECS <-> outer port DiagInfoRCECS
    delegate TestLin.LIN_LightMode_Status_1 <-> outer port LIN_LightMode_Status_1
    delegate TestLin.LIN_WRUpButtonStatus <-> outer port LIN_WRUpButtonStatus
    delegate TestLin.LIN_DifflockDeactivationBtn_st <-> outer port LIN_DifflockDeactivationBtn_st
    delegate TestLin.LIN_IntLghtCenterBtnFreeWhl_s <-> outer port LIN_IntLghtCenterBtnFreeWhl_s
    delegate TestLin.SwitchDetectionResp1L5 <-> outer port SwitchDetectionResp1L5
    delegate TestLin.FSP1DiagInfoL5 <-> outer port FSP1DiagInfoL5
    delegate TestLin.LIN_EscButtonMuddySiteStatus <-> outer port LIN_EscButtonMuddySiteStatus
    delegate TestLin.FSP1SwitchStatusL5 <-> outer port FSP1SwitchStatusL5
    delegate TestLin.SwitchDetectionNeeded1L4 <-> outer port SwitchDetectionNeeded1L4
    delegate TestLin.LIN_AdjustButtonStatus <-> outer port LIN_AdjustButtonStatus
    delegate TestLin.ResponseErrorDLFW <-> outer port ResponseErrorDLFW
    delegate TestLin.LIN_BlackPanelMode_ButtonStat <-> outer port LIN_BlackPanelMode_ButtonStat
    delegate TestLin.FSP1DiagInfoL4 <-> outer port FSP1DiagInfoL4
    delegate TestLin.LIN_FCWPushButton <-> outer port LIN_FCWPushButton
    delegate TestLin.ResponseErrorRCECS <-> outer port ResponseErrorRCECS
    delegate TestLin.DiagInfoELCP2 <-> outer port DiagInfoELCP2
    delegate TestLin.DiagInfoCCFW <-> outer port DiagInfoCCFW
    delegate TestLin.DiagInfoILCP2 <-> outer port DiagInfoILCP2
    delegate TestLin.DiagInfoELCP1 <-> outer port DiagInfoELCP1
    delegate TestLin.LIN_BackLightDimming_Status <-> outer port LIN_BackLightDimming_Status
    delegate TestLin.FSP1ResponseErrorL5 <-> outer port FSP1ResponseErrorL5
    delegate TestLin.LIN_DRL_ButtonStatus <-> outer port LIN_DRL_ButtonStatus
    delegate TestLin.ResponseErrorELCP2 <-> outer port ResponseErrorELCP2
    delegate TestLin.ResponseErrorCCFW <-> outer port ResponseErrorCCFW
    delegate TestLin.LIN_LevelingThumbwheel_stat <-> outer port LIN_LevelingThumbwheel_stat
    delegate TestLin.LIN_Offroad_ButtonStatus <-> outer port LIN_Offroad_ButtonStatus
    delegate TestLin.LIN_FogLightFront_ButtonStat_2 <-> outer port LIN_FogLightFront_ButtonStat_2
    delegate TestLin.LIN_RearWorkProjector_BtnStat <-> outer port LIN_RearWorkProjector_BtnStat
    delegate TestLin.LIN_HeadLampUpDown_SwitchStatu <-> outer port LIN_HeadLampUpDown_SwitchStatu
    delegate TestLin.LIN_FogLightFront_ButtonStat_1 <-> outer port LIN_FogLightFront_ButtonStat_1
    delegate TestLin.LIN_IntLghtMaxModeBtnPnl2_s <-> outer port LIN_IntLghtMaxModeBtnPnl2_s
    delegate TestLin.LIN_IntLghtRestModeBtnPnl2_s <-> outer port LIN_IntLghtRestModeBtnPnl2_s
    delegate TestLin.LIN_ACCOrCCIndication <-> outer port LIN_ACCOrCCIndication
    delegate TestLin.LIN_M3_DeviceIndication <-> outer port LIN_M3_DeviceIndication
    delegate TestLin.LIN_EscButtonMuddySiteDeviceIn <-> outer port LIN_EscButtonMuddySiteDeviceIn
    delegate TestLin.LIN_M1_DeviceIndication <-> outer port LIN_M1_DeviceIndication
    delegate TestLin.LIN_ShortPulseMaxLength <-> outer port LIN_ShortPulseMaxLength
    delegate TestLin.LIN_FCW_DeviceIndication <-> outer port LIN_FCW_DeviceIndication
    delegate TestLin.LIN_DrivingLightPlus_Indicatio <-> outer port LIN_DrivingLightPlus_Indicatio
    delegate TestLin.LIN_RearFog_Indication <-> outer port LIN_RearFog_Indication
    delegate TestLin.LIN_Offroad_Indication <-> outer port LIN_Offroad_Indication
    delegate TestLin.LIN_LKS_DeviceIndication <-> outer port LIN_LKS_DeviceIndication
    delegate TestLin.LIN_Down_DeviceIndication <-> outer port LIN_Down_DeviceIndication
    delegate TestLin.LIN_M2_DeviceIndication <-> outer port LIN_M2_DeviceIndication
    delegate TestLin.LIN_ParkingLight_Indication <-> outer port LIN_ParkingLight_Indication
    delegate TestLin.FSP1IndicationCmdL5 <-> outer port FSP1IndicationCmdL5
    delegate TestLin.LIN_FrontFog_Indication <-> outer port LIN_FrontFog_Indication
    delegate TestLin.LIN_ASLIndication <-> outer port LIN_ASLIndication
    delegate TestLin.LIN_DaytimeRunningLight_Indica <-> outer port LIN_DaytimeRunningLight_Indica
    delegate TestLin.LIN_DifflockOnOff_Indication <-> outer port LIN_DifflockOnOff_Indication
    delegate TestLin.LIN_RearWorkProjector_Indicati <-> outer port LIN_RearWorkProjector_Indicati
    delegate TestLin.FSP1IndicationCmdL4 <-> outer port FSP1IndicationCmdL4
    delegate TestLin.LIN_Adjust_DeviceIndication <-> outer port LIN_Adjust_DeviceIndication
    delegate TestLin.LIN_DrivingLight_Indication <-> outer port LIN_DrivingLight_Indication
    delegate TestLin.LIN_Up_DeviceIndication <-> outer port LIN_Up_DeviceIndication
    connect IOHWAB.AdInterfaces_P -> PVTApp_AdiInterfaces.AdiInterfaces_P
    connect IOHWAB.Do12VInterface_P -> PVTApp_Do12VInterface.Do12VInterface_P
    connect IOHWAB.DobhsCtrlInterface_P_2 -> PVTApp_DobhsCtrlInterface.DobhsCtrlInterface_P_2
    connect IOHWAB.DobhsCtrlInterface_P_1 -> PVTApp_DobhsCtrlInterface.DobhsCtrlInterface_P_1
    connect IOHWAB.DobhsCtrlInterface_P_3 -> PVTApp_DobhsCtrlInterface.DobhsCtrlInterface_P_3
    connect IOHWAB.DobhsCtrlInterface_P_4 -> PVTApp_DobhsCtrlInterface.DobhsCtrlInterface_P_4
    delegate PVTApp_AdiInterfaces.Debug_PVT_SCIM_Ctrl_LivingPullUp <-> outer port Debug_PVT_SCIM_Ctrl_LivingPullUp
    delegate PVTApp_AdiInterfaces.Debug_PVT_SCIM_Ctrl_ParkedPullUp <-> outer port Debug_PVT_SCIM_Ctrl_ParkedPullUp
    delegate PVTApp_AdiInterfaces.ABSInhibitRqstDenied <-> outer port ABSInhibitRqstDenied
    delegate PVTApp_AdiInterfaces.Debug_PVT_SCIM_RD_12VLivingVolt <-> outer port Debug_PVT_SCIM_RD_12VLivingVolt
    delegate PVTApp_AdiInterfaces.Debug_PVT_SCIM_RD_12VParkedVolt <-> outer port Debug_PVT_SCIM_RD_12VParkedVolt
    delegate PVTApp_Do12VInterface.Debug_PVT_SCIM_RD_12VDCDCFault <-> outer port Debug_PVT_SCIM_RD_12VDCDCFault
    delegate PVTApp_Do12VInterface.Debug_PVT_SCIM_RD_12VDCDCVolt <-> outer port Debug_PVT_SCIM_RD_12VDCDCVolt
    delegate PVTApp_Do12VInterface.Debug_PVT_SCIM_RD_VBAT <-> outer port Debug_PVT_SCIM_RD_VBAT
    delegate PVTApp_DowhsDowlsInterface.Debug_PVT_SCIM_Ctrl_WLS2Freq <-> outer port Debug_PVT_SCIM_Ctrl_WLS2Freq
    delegate PVTApp_DowhsDowlsInterface.Debug_PVT_SCIM_Ctrl_WLS3 <-> outer port Debug_PVT_SCIM_Ctrl_WLS3
    delegate PVTApp_DowhsDowlsInterface.Debug_PVT_SCIM_Ctrl_WLS2Duty <-> outer port Debug_PVT_SCIM_Ctrl_WLS2Duty
    delegate PVTApp_DowhsDowlsInterface.Debug_PVT_SCIM_Ctrl_WLS1_Duty <-> outer port Debug_PVT_SCIM_Ctrl_WLS1_Duty
    delegate PVTApp_DowhsDowlsInterface.Debug_PVT_SCIM_Ctrl_WHS1 <-> outer port Debug_PVT_SCIM_Ctrl_WHS1
    delegate PVTApp_DowhsDowlsInterface.Debug_PVT_SCIM_Ctrl_WHS1_Freq <-> outer port Debug_PVT_SCIM_Ctrl_WHS1_Freq
    delegate PVTApp_DowhsDowlsInterface.Debug_PVT_SCIM_Ctrl_WLS3Duty <-> outer port Debug_PVT_SCIM_Ctrl_WLS3Duty
    delegate PVTApp_DowhsDowlsInterface.Debug_PVT_SCIM_Ctrl_WHS1_Duty <-> outer port Debug_PVT_SCIM_Ctrl_WHS1_Duty
    delegate PVTApp_DowhsDowlsInterface.Debug_PVT_SCIM_Ctrl_WLS1_Freq <-> outer port Debug_PVT_SCIM_Ctrl_WLS1_Freq
    delegate PVTApp_DowhsDowlsInterface.Debug_PVT_SCIM_Ctrl_WLS3Freq <-> outer port Debug_PVT_SCIM_Ctrl_WLS3Freq
    delegate PVTApp_DowhsDowlsInterface.Debug_PVT_SCIM_Ctrl_WHS2 <-> outer port Debug_PVT_SCIM_Ctrl_WHS2
    delegate PVTApp_DowhsDowlsInterface.Debug_PVT_SCIM_Ctrl_WLS2 <-> outer port Debug_PVT_SCIM_Ctrl_WLS2
    delegate PVTApp_DowhsDowlsInterface.Debug_PVT_SCIM_Ctrl_WHS2_Freq <-> outer port Debug_PVT_SCIM_Ctrl_WHS2_Freq
    delegate PVTApp_DowhsDowlsInterface.Debug_PVT_SCIM_Ctrl_WLS1 <-> outer port Debug_PVT_SCIM_Ctrl_WLS1
    delegate PVTApp_DowhsDowlsInterface.Debug_PVT_SCIM_Ctrl_WHS2_Duty <-> outer port Debug_PVT_SCIM_Ctrl_WHS2_Duty
    delegate PVTApp_DowhsDowlsInterface.Debug_PVT_SCIM_RD_WLS1_Duty <-> outer port Debug_PVT_SCIM_RD_WLS1_Duty
    delegate PVTApp_DowhsDowlsInterface.Debug_PVT_SCIM_RD_WLS3_Freq <-> outer port Debug_PVT_SCIM_RD_WLS3_Freq
    delegate PVTApp_DowhsDowlsInterface.Debug_PVT_SCIM_RD_WHS1_Volt <-> outer port Debug_PVT_SCIM_RD_WHS1_Volt
    delegate PVTApp_DowhsDowlsInterface.Debug_PVT_SCIM_RD_WLS2_Fault <-> outer port Debug_PVT_SCIM_RD_WLS2_Fault
    delegate PVTApp_DowhsDowlsInterface.Debug_PVT_SCIM_RD_WLS1_Volt <-> outer port Debug_PVT_SCIM_RD_WLS1_Volt
    delegate PVTApp_DowhsDowlsInterface.Debug_PVT_SCIM_RD_WHS2_Volt <-> outer port Debug_PVT_SCIM_RD_WHS2_Volt
    delegate PVTApp_DowhsDowlsInterface.Debug_PVT_SCIM_RD_WHS1_Duty <-> outer port Debug_PVT_SCIM_RD_WHS1_Duty
    delegate PVTApp_DowhsDowlsInterface.Debug_PVT_SCIM_RD_WLS2_Volt <-> outer port Debug_PVT_SCIM_RD_WLS2_Volt
    delegate PVTApp_DowhsDowlsInterface.Debug_PVT_SCIM_RD_WLS1_Fault <-> outer port Debug_PVT_SCIM_RD_WLS1_Fault
    delegate PVTApp_DowhsDowlsInterface.Debug_PVT_SCIM_RD_WLS2_Freq <-> outer port Debug_PVT_SCIM_RD_WLS2_Freq
    delegate PVTApp_DowhsDowlsInterface.Debug_PVT_SCIM_RD_WHS2_Duty <-> outer port Debug_PVT_SCIM_RD_WHS2_Duty
    delegate PVTApp_DowhsDowlsInterface.Debug_PVT_SCIM_RD_WHS1_Freq <-> outer port Debug_PVT_SCIM_RD_WHS1_Freq
    delegate PVTApp_DowhsDowlsInterface.Debug_PVT_SCIM_RD_WLS2_Duty <-> outer port Debug_PVT_SCIM_RD_WLS2_Duty
    delegate PVTApp_DowhsDowlsInterface.Debug_PVT_SCIM_RD_WHS1_Fault <-> outer port Debug_PVT_SCIM_RD_WHS1_Fault
    delegate PVTApp_DowhsDowlsInterface.Debug_PVT_SCIM_RD_WHS2_Freq <-> outer port Debug_PVT_SCIM_RD_WHS2_Freq
    delegate PVTApp_DowhsDowlsInterface.Debug_PVT_SCIM_RD_WLS3_Duty <-> outer port Debug_PVT_SCIM_RD_WLS3_Duty
    delegate PVTApp_DowhsDowlsInterface.Debug_PVT_SCIM_RD_WHS2_Fault <-> outer port Debug_PVT_SCIM_RD_WHS2_Fault
    delegate PVTApp_DowhsDowlsInterface.Debug_PVT_SCIM_RD_WLS3_Fault <-> outer port Debug_PVT_SCIM_RD_WLS3_Fault
    delegate PVTApp_DowhsDowlsInterface.Debug_PVT_SCIM_RD_WLS1_Freq <-> outer port Debug_PVT_SCIM_RD_WLS1_Freq
    delegate PVTApp_DowhsDowlsInterface.Debug_PVT_SCIM_RD_WLS3_Volt <-> outer port Debug_PVT_SCIM_RD_WLS3_Volt
    delegate PVTApp_Do12VInterface.Debug_PVT_SCIM_Ctrl_12VDCDC <-> outer port Debug_PVT_SCIM_Ctrl_12VDCDC
    delegate PVTApp_Do12VInterface.Debug_PVT_SCIM_Ctrl_12VParked <-> outer port Debug_PVT_SCIM_Ctrl_12VParked
    delegate PVTApp_Do12VInterface.Debug_PVT_SCIM_Ctrl_12VLiving <-> outer port Debug_PVT_SCIM_Ctrl_12VLiving
    connect CDD_LFIC.LfICInit_P -> PEPS.LfICInit_P
    connect CDD_LFIC.SetupLfTelegram_P -> PEPS.SetupLfTelegram_P
    connect CDD_LFIC.TimeoutTxTelegram_P -> PEPS.TimeoutTxTelegram_P
    connect CDD_RFIC.RficInit_P -> PEPS.RficInit_P
    connect CDD_RFIC.RficIRQActiveCheck_P -> PEPS.rficIRQActiveCheck_P
    connect CDD_RFIC.RficIRQPendingCheck_P -> PEPS.rficIRQPendingCheck_P
    connect CDD_RFIC.RficSysModeConfirm_P -> PEPS.RficSysModeConfirm_P
    connect CDD_RFIC.SearchSysMode_P -> PEPS.SearchSysMode_P
    connect PEPS.SetValidFobFoundResult_P -> CDD_RFIC.SetValidFobFoundResult_P
    connect IOHWAB.LficNRESDio_P -> CDD_LFIC.LficNRESDio_R
    connect IOHWAB.LficICU_P -> CDD_LFIC.LficICU_R
    connect IOHWAB.RficICU_P -> CDD_RFIC.RficICU_R
    connect IOHWAB.RficNRESDio_P -> CDD_RFIC.RficNRESDio_R
    connect IOHWAB.DowlsInterface_P_2 -> PVTApp_DowhsDowlsInterface.DowlsInterface_P_2
    connect IOHWAB.DowlsInterface_P_1 -> PVTApp_DowhsDowlsInterface.DowlsInterface_P_1
    connect IOHWAB.DowlsInterface_P_3 -> PVTApp_DowhsDowlsInterface.DowlsInterface_P_3
    connect IOHWAB.DowhsInterfaces_P_2 -> PVTApp_DowhsDowlsInterface.DowhsInterfaces_P_2
    connect IOHWAB.DowhsInterfaces_P_1 -> PVTApp_DowhsDowlsInterface.DowhsInterfaces_P_1
    connect PEPS.ClearHighFixCheckTimer_P -> CDD_RFIC.CleaHighFixCheckTimer_P
    connect IOHWAB.LficNRESDio_P -> PEPS.LficNRESDio_R
    delegate PEPS.Debug_PVT_PEPS_VDSI_Ctrl_P <-> outer port Debug_PVT_PEPS_VDSI_Ctrl_P
    delegate PEPS.Debug_PVT_PEPS_GainP2_Ctrl_P <-> outer port Debug_PVT_PEPS_GainP2_Ctrl_P
    delegate PEPS.Debug_PVT_PEPS_GainP3_Ctrl_P <-> outer port Debug_PVT_PEPS_GainP3_Ctrl_P
    delegate PEPS.Debug_PVT_PEPS_GainP1_Ctrl_P <-> outer port Debug_PVT_PEPS_GainP1_Ctrl_P
    delegate PEPS.Debug_PVT_PEPS_GainP4_Ctrl_P <-> outer port Debug_PVT_PEPS_GainP4_Ctrl_P
    delegate PEPS.Debug_PVT_PEPS_Ant_Ctrl_P <-> outer port Debug_PVT_PEPS_Ant_Ctrl_P
    delegate PEPS.Debug_PVT_PEPS_P4_MaxRSSI_P <-> outer port Debug_PVT_PEPS_P4_MaxRSSI_P
    delegate PEPS.Debug_PVT_PEPS_GainP1_stat_P <-> outer port Debug_PVT_PEPS_GainP1_stat_P
    delegate PEPS.Debug_PVT_PEPS_P2_MaxRSSI_P <-> outer port Debug_PVT_PEPS_P2_MaxRSSI_P
    delegate PEPS.Debug_PVT_PEPS_P3_MaxRSSI_P <-> outer port Debug_PVT_PEPS_P3_MaxRSSI_P
    delegate PEPS.Debug_PVT_PEPS_AntCtrl_stat_P <-> outer port Debug_PVT_PEPS_AntCtrl_stat_P
    delegate PEPS.Debug_PVT_PEPS_GainP3_stat_P <-> outer port Debug_PVT_PEPS_GainP3_stat_P
    delegate PEPS.Debug_PVT_PEPS_GainP4_stat_P <-> outer port Debug_PVT_PEPS_GainP4_stat_P
    delegate PEPS.Debug_PVT_PEPS_VDSI_stat_P <-> outer port Debug_PVT_PEPS_VDSI_stat_P
    delegate PEPS.Debug_PVT_PEPS_GainP2_stat_P <-> outer port Debug_PVT_PEPS_GainP2_stat_P
    delegate PEPS.Debug_PVT_PEPS_P1_MaxRSSI_P <-> outer port Debug_PVT_PEPS_P1_MaxRSSI_P
    delegate PEPS.Debug_PVT_PEPS_Logic_stat_P <-> outer port Debug_PVT_PEPS_Logic_stat_P
    connect PEPS.st_DstBlock_P -> CDD_LFIC.st_DstBlock_P
    connect CDD_LFIC.SetupDST_Telegram_P -> PEPS.SetupDST_Telegram_P
    connect PEPS.b_DST_ResponseNG_P -> CDD_LFIC.b_DST_ResponseNG_R
    connect PEPS.b_DST_RxCompleteFlag_P -> CDD_LFIC.b_DST_RxCompleteFlag_R
    connect CDD_LFIC.b_DST_RxCompleteFlag_P -> PEPS.b_DST_RxCompleteFlag_R
    connect CDD_LFIC.b_DST_ResponseNG_P -> PEPS.b_DST_ResponseNG_R
